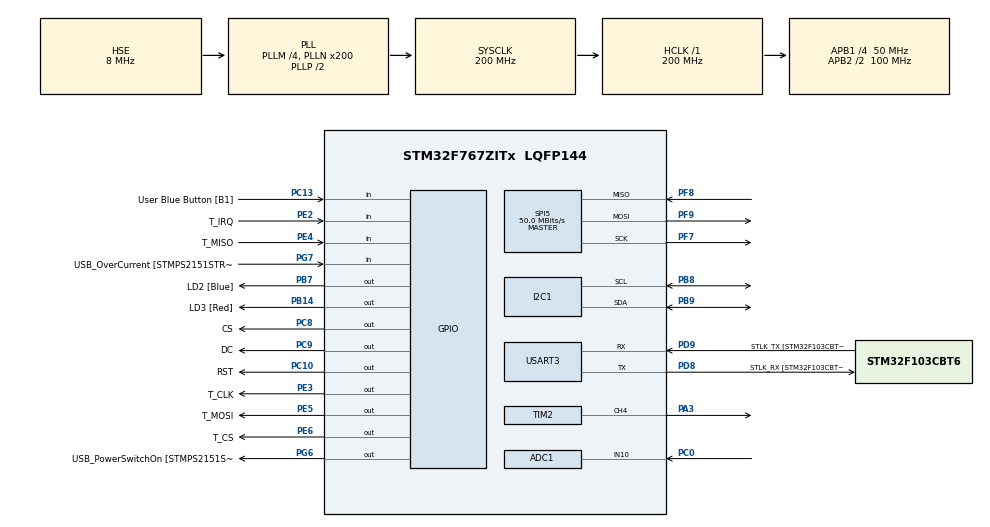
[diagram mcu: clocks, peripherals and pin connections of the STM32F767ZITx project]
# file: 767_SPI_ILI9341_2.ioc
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ADC1.Channel-0\#ChannelRegularConversion=ADC_CHANNEL_10
ADC1.ContinuousConvMode=ENABLE
ADC1.EOCSelection=ADC_EOC_SEQ_CONV
ADC1.NbrOfConversionFlag=1
ADC1.Rank-0\#ChannelRegularConversion=1
ADC1.SamplingTime-0\#ChannelRegularConversion=ADC_SAMPLETIME_3CYCLES
ADC1.master=1
CORTEX_M7.ART_ACCLERATOR_ENABLE=1
CORTEX_M7.CPU_DCache=Enabled
CORTEX_M7.CPU_ICache=Enabled
CORTEX_M7.PREFETCH_ENABLE=1
I2C1.Timing=0x00C0EAFF
Mcu.Family=STM32F7
Mcu.Name=STM32F767ZITx
Mcu.Package=LQFP144
NVIC.PriorityGroup=NVIC_PRIORITYGROUP_2
NVIC.TIM1_UP_TIM10_IRQn=true\:1\:0\:true\:false\:true\:true\:true\:true
PA1.GPIO_Label=RMII_REF_CLK [LAN8742A-CZ-TR_REFCLK0]
PA1.Signal=ETH_REF_CLK
PA13.GPIO_Label=TMS
PA13.Mode=Serial_Wire
PA13.Signal=SYS_JTMS-SWDIO
PA14.GPIO_Label=TCK
PA14.Mode=Serial_Wire
PA14.Signal=SYS_JTCK-SWCLK
PA2.Signal=S_TIM2_CH3
PA3.GPIO_Speed=GPIO_SPEED_FREQ_VERY_HIGH
PA3.Signal=S_TIM2_CH4
PA7.GPIO_Label=RMII_CRS_DV [LAN8742A-CZ-TR_CRS_DV]
PA7.Signal=ETH_CRS_DV
PB13.GPIO_Label=RMII_TXD1 [LAN8742A-CZ-TR_TXD1]
PB13.Signal=ETH_TXD1
PB14.GPIO_Label=LD3 [Red]
PB14.Signal=GPIO_Output
PB3.GPIO_Label=SWO
PB3.Signal=SYS_JTDO-SWO
PB7.GPIO_Label=LD2 [Blue]
PB7.Signal=GPIO_Output
PB8.Mode=I2C
PB8.Signal=I2C1_SCL
PB9.Mode=I2C
PB9.Signal=I2C1_SDA
PC0.Signal=ADCx_IN10
PC1.GPIO_Label=RMII_MDC [LAN8742A-CZ-TR_MDC]
PC1.Signal=ETH_MDC
PC10.GPIO_Label=RST
PC10.GPIO_Speed=GPIO_SPEED_FREQ_VERY_HIGH
PC10.Signal=GPIO_Output
PC13.GPIO_Label=User Blue Button [B1]
PC13.Signal=GPIO_Input
PC14/OSC32_IN.Mode=LSE-External-Oscillator
PC14/OSC32_IN.Signal=RCC_OSC32_IN
PC15/OSC32_OUT.Mode=LSE-External-Oscillator
PC15/OSC32_OUT.Signal=RCC_OSC32_OUT
PC4.GPIO_Label=RMII_RXD0 [LAN8742A-CZ-TR_RXD0]
PC4.Signal=ETH_RXD0
PC5.GPIO_Label=RMII_RXD1 [LAN8742A-CZ-TR_RXD1]
PC5.Signal=ETH_RXD1
PC8.GPIO_Label=CS
PC8.GPIO_Speed=GPIO_SPEED_FREQ_VERY_HIGH
PC8.Signal=GPIO_Output
PC9.GPIO_Label=DC
PC9.GPIO_Speed=GPIO_SPEED_FREQ_VERY_HIGH
PC9.Signal=GPIO_Output
PD8.GPIO_Label=STLK_RX [STM32F103CBT6_PA3]
PD8.Mode=Asynchronous
PD8.Signal=USART3_TX
PD9.GPIO_Label=STLK_TX [STM32F103CBT6_PA2]
PD9.Mode=Asynchronous
PD9.Signal=USART3_RX
PE2.GPIO_Label=T_IRQ
PE2.Signal=GPIO_Input
PE3.GPIO_Label=T_CLK
PE3.GPIO_Speed=GPIO_SPEED_FREQ_VERY_HIGH
PE3.Signal=GPIO_Output
PE4.GPIO_Label=T_MISO
PE4.Signal=GPIO_Input
PE5.GPIO_Label=T_MOSI
PE5.GPIO_Speed=GPIO_SPEED_FREQ_VERY_HIGH
PE5.Signal=GPIO_Output
PE6.GPIO_Label=T_CS
PE6.GPIO_Speed=GPIO_SPEED_FREQ_VERY_HIGH
PE6.Signal=GPIO_Output
PF7.Mode=Full_Duplex_Master
PF7.Signal=SPI5_SCK
PF8.Mode=Full_Duplex_Master
PF8.Signal=SPI5_MISO
PF9.Mode=Full_Duplex_Master
PF9.Signal=SPI5_MOSI
PG11.GPIO_Label=RMII_TX_EN [LAN8742A-CZ-TR_TXEN]
PG11.Signal=ETH_TX_EN
PG13.GPIO_Label=RMII_TXD0 [LAN8742A-CZ-TR_TXD0]
PG13.Signal=ETH_TXD0
PG6.GPIO_Label=USB_PowerSwitchOn [STMPS2151STR_EN]
PG6.Signal=GPIO_Output
PG7.GPIO_Label=USB_OverCurrent [STMPS2151STR_FAULT]
PG7.Signal=GPIO_Input
PH0/OSC_IN.GPIO_Label=MCO [STM32F103CBT6_PA8]
PH0/OSC_IN.Mode=HSE-External-Clock-Source
PH0/OSC_IN.Signal=RCC_OSC_IN
PH1/OSC_OUT.Mode=HSE-External-Clock-Source
PH1/OSC_OUT.Signal=RCC_OSC_OUT
ProjectManager.HeapSize=0x200
ProjectManager.StackSize=0x400
ProjectManager.TargetToolchain=STM32CubeIDE
RCC.48MHZClocksFreq_Value=24000000
RCC.AHBFreq_Value=200000000
RCC.APB1CLKDivider=RCC_HCLK_DIV4
RCC.APB1Freq_Value=50000000
RCC.APB1TimFreq_Value=100000000
RCC.APB2CLKDivider=RCC_HCLK_DIV2
RCC.APB2Freq_Value=100000000
RCC.APB2TimFreq_Value=200000000
RCC.CortexFreq_Value=200000000
RCC.HCLKFreq_Value=200000000
RCC.HSE_VALUE=8000000
RCC.HSI_VALUE=16000000
RCC.PLLM=4
RCC.PLLMUL=RCC_PLL_MUL9
RCC.PLLN=200
RCC.PLLQ=9
RCC.PLLSourceVirtual=RCC_PLLSOURCE_HSE
RCC.PRESCALERUSB=RCC_USBCLKSOURCE_PLL_DIV1_5
RCC.SYSCLKFreq_VALUE=200000000
RCC.SYSCLKSource=RCC_SYSCLKSOURCE_PLLCLK
RCC.SYSCLKSourceVirtual=RCC_SYSCLKSOURCE_PLLCLK
RCC.USBFreq_Value=44444444.44444445
RCC.VCOOutputFreq_Value=400000000
SH.ADCx_IN10.0=ADC1_IN10,IN10
SH.S_TIM2_CH3.0=TIM2_CH3
SH.S_TIM2_CH4.0=TIM2_CH4,PWM Generation4 CH4
SPI5.CalculateBaudRate=50.0 MBits/s
SPI5.DataSize=SPI_DATASIZE_8BIT
SPI5.Direction=SPI_DIRECTION_2LINES
SPI5.Mode=SPI_MODE_MASTER
SPI5.NSSPMode=SPI_NSS_PULSE_DISABLE
SPI5.VirtualType=VM_MASTER
TIM1.ClockDivision=TIM_CLOCKDIVISION_DIV1
TIM1.Period=10000-1
TIM1.Prescaler=21600-1
TIM2.Channel-PWM\ Generation4\ CH4=TIM_CHANNEL_4
TIM2.Period=10000-1
TIM2.Prescaler=108-1
TIM2.Pulse-PWM\ Generation4\ CH4=10000/4-1
USART3.VirtualMode-Asynchronous=VM_ASYNC
VP_RNG_VS_RNG.Mode=RNG_Activate
VP_TIM1_VS_ClockSourceINT.Mode=Internal
VP_TIM2_VS_ClockSourceINT.Mode=Internal
board=NUCLEO-F767ZI

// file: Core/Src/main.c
/* USER CODE BEGIN Header */
/**
  ******************************************************************************
  * @file           : main.c
  * @brief          : Main program body
  ******************************************************************************
  * @attention
  *
  * <h2><center>&copy; Copyright (c) 2021 STMicroelectronics.
  * All rights reserved.</center></h2>
  *
  * This software component is licensed by ST under BSD 3-Clause license,
  * the "License"; You may not use this file except in compliance with the
  * License. You may obtain a copy of the License at:
  *                        opensource.org/licenses/BSD-3-Clause
  *
  ******************************************************************************
  */
/* USER CODE END Header */
#include "main.h"
#include "adc.h"
#include "i2c.h"
#include "rng.h"
#include "spi.h"
#include "tim.h"
#include "usart.h"
#include "gpio.h"

/* USER CODE BEGIN Includes */
#include "stdio.h"
#include "ILI9341_Touchscreen.h"

#include "ILI9341_STM32_Driver.h"
#include "ILI9341_GFX.h"
#include "string.h"
/* USER CODE END Includes */

/* USER CODE BEGIN PTD */
typedef enum {
    MENU,
    PROFILE
} State;
/* USER CODE END PTD */

/* USER CODE BEGIN PV */
/* Private variables ---------------------------------------------------------*/
uint8_t red = 0;
uint8_t red_percent = 0;
uint8_t green = 0;
uint8_t green_percent = 0;
uint8_t blue = 0;
uint8_t blue_percent = 0;
float h=30.0,t=40.0;
uint8_t profile_counter = 0;
uint8_t profile_active = 0;
const uint16_t bill[] = {
		0xffff, 0xffff, 0xffff, 0xffff, 0xffff, 0xffff, 0xdf1c, 0xb5d7, 0xb596, 0xbe39, 0xefdf, 0xffff, 0xffff, 0xffff, 0xffff, 0xffff, 0xffff, 0xffff, 0xffff, 0xffff, 0xffff, 0xffff, 0xffff, 0xffff, 0xffff, 0xffff, 0xffff, 0xffff, 0xffff, 0xf7df, 0xf7be, 0xf7be, 0xf7be, 0xf7be, 0xf7be, 0xf7be, 0xf7be, 0xef9e, 0xdf3d, 0xb69c, 0x8e1c, 0x9ebf, 0xaf1f, 0x9e9e, 0xb6dd, 0xefbf, 0xffff, 0xf7df, 0xdf3c, 0xdf1c, 0xef7e, 0xef7e, 0xe77d, 0xef7e, 0xe75d, 0xe75d, 0xe75d, 0xe77d, 0xef7e, 0xef7e, 0xef7e, 0xe77d, 0xe75d, 0xe75d, 0xe73d, 0xe73d, 0xe73d, 0xe75d, 0xe73d, 0xe71c, 0xdefc, 0xe75d, 0xffff, 0xffff, 0xffff, 0xffff, 0xf7df, 0xf7be, 0xef7e, 0xe73c,
		0xffff, 0xffff, 0xffff, 0xffff, 0xffff, 0xffff, 0xef7e, 0xceba, 0xbe39, 0xc69a, 0xf7bf, 0xffff, 0xffff, 0xffff, 0xffff, 0xffff, 0xffff, 0xffff, 0xffff, 0xffff, 0xffff, 0xffff, 0xffff, 0xffff, 0xffff, 0xffff, 0xffff, 0xffff, 0xffff, 0xf7df, 0xf79e, 0xf7be, 0xf7be, 0xf7be, 0xf7be, 0xf7be, 0xf79e, 0xf7bf, 0xdf5e, 0xb69c, 0x95fa, 0x95fa, 0x9e1b, 0x9e7d, 0xa63b, 0x9514, 0x9d35, 0x9d35, 0x9d14, 0xa555, 0xadd7, 0xe75d, 0xef7e, 0xe75d, 0xe75d, 0xe75d, 0xe75d, 0xef7e, 0xef7e, 0xef7e, 0xef7e, 0xef7e, 0xe77d, 0xe75d, 0xe73d, 0xe73d, 0xe73d, 0xe73d, 0xe73d, 0xe73d, 0xe71c, 0xef5d, 0xffff, 0xffff, 0xffff, 0xffdf, 0xf7df, 0xf7be, 0xef7e, 0xef5c,
		0xffff, 0xffff, 0xffff, 0xffff, 0xffff, 0xffff, 0xffff, 0xf7df, 0xefbe, 0xef9e, 0xffdf, 0xffff, 0xffff, 0xffff, 0xffff, 0xffff, 0xffff, 0xffff, 0xffff, 0xffff, 0xffff, 0xffff, 0xffff, 0xffff, 0xffff, 0xffff, 0xffff, 0xffff, 0xffff, 0xf7bf, 0xef9e, 0xf79e, 0xf7be, 0xf7be, 0xf7be, 0xf7be, 0xffff, 0xdf1c, 0xadd8, 0x7c52, 0x52cc, 0x424a, 0x4249, 0x530d, 0x4a8b, 0x2966, 0x2145, 0x2966, 0x39e8, 0x73af, 0x636d, 0x94d3, 0xce7a, 0xceba, 0xef7e, 0xe75d, 0xe75d, 0xe77d, 0xef7e, 0xef7e, 0xef7e, 0xef7e, 0xef7d, 0xe75d, 0xe73d, 0xe73d, 0xe75d, 0xe75d, 0xe75d, 0xef5d, 0xef3d, 0xef7e, 0xffff, 0xffff, 0xffff, 0xffdf, 0xf7df, 0xf7be, 0xef9e, 0xe75d,
		0xffff, 0xffff, 0xffff, 0xffff, 0xffff, 0xffff, 0xffff, 0xffff, 0xffff, 0xffff, 0xffff, 0xffff, 0xffff, 0xffff, 0xffff, 0xffff, 0xffff, 0xffff, 0xffff, 0xffff, 0xffff, 0xffff, 0xffff, 0xffff, 0xffff, 0xffff, 0xffff, 0xffff, 0xffff, 0xf7bf, 0xef9e, 0xf7be, 0xf7be, 0xf7be, 0xf7df, 0xffdf, 0xbe38, 0x636e, 0x5b0c, 0x52ec, 0x39e8, 0x39e8, 0x31c7, 0x31a7, 0x31a6, 0x3186, 0x3186, 0x2966, 0x3186, 0x3186, 0x31a7, 0x4249, 0x8451, 0xad96, 0xef7e, 0xe75d, 0xe75d, 0xe75d, 0xef7e, 0xef7e, 0xef7e, 0xef7d, 0xef5d, 0xe75d, 0xe73d, 0xe73d, 0xef7e, 0xef7e, 0xef7e, 0xef7d, 0xef5d, 0xef7e, 0xffff, 0xffff, 0xffff, 0xffdf, 0xf7df, 0xf7bf, 0xef9e, 0xef5d,
		0xffff, 0xffff, 0xffff, 0xffff, 0xffff, 0xffff, 0xffff, 0xffff, 0xffff, 0xffff, 0xffff, 0xffff, 0xffff, 0xffff, 0xffff, 0xffff, 0xffff, 0xffff, 0xffff, 0xffff, 0xffff, 0xffff, 0xffff, 0xffff, 0xffff, 0xffff, 0xffff, 0xffff, 0xffff, 0xf7df, 0xef9e, 0xf7be, 0xf7de, 0xffff, 0xffff, 0xa535, 0x4a6a, 0x4a8a, 0x4a8a, 0x4249, 0x39e8, 0x31c7, 0x3186, 0x2986, 0x31c7, 0x3186, 0x2966, 0x2966, 0x2966, 0x3186, 0x3186, 0x3186, 0x3a08, 0x52cb, 0xa555, 0xe77e, 0xe77e, 0xe75d, 0xe77d, 0xef7e, 0xef7e, 0xef5d, 0xef5d, 0xe73d, 0xe73d, 0xe73d, 0xe75d, 0xe75d, 0xe75d, 0xe75d, 0xe75d, 0xef7e, 0xffdf, 0xffff, 0xffff, 0xffdf, 0xf7df, 0xf7be, 0xef7e, 0xef5d,
		0xffff, 0xffff, 0xffff, 0xffff, 0xffff, 0xffff, 0xffff, 0xffff, 0xffff, 0xffff, 0xffff, 0xffff, 0xffff, 0xffff, 0xffff, 0xffff, 0xffff, 0xffff, 0xffff, 0xffff, 0xffff, 0xffff, 0xffff, 0xffff, 0xffff, 0xffff, 0xffff, 0xffff, 0xffff, 0xf7df, 0xef9e, 0xf7be, 0xffff, 0xdf1c, 0x8c92, 0x4a6a, 0x4a8a, 0x4a6a, 0x39e8, 0x31c7, 0x31a7, 0x2986, 0x31a7, 0x2986, 0x2986, 0x2966, 0x2966, 0x2945, 0x2145, 0x2125, 0x2965, 0x2965, 0x2965, 0x2965, 0x3a08, 0x94f4, 0xe75d, 0xef7e, 0xe77d, 0xef7d, 0xef7e, 0xef7e, 0xef5d, 0xe75d, 0xe75d, 0xe75d, 0xe77e, 0xef7e, 0xef7e, 0xef9e, 0xef9e, 0xf7bf, 0xffff, 0xffff, 0xffff, 0xffdf, 0xf7df, 0xf7be, 0xef7d, 0xe73c,
		0xffff, 0xffff, 0xffff, 0xffff, 0xffff, 0xffff, 0xffff, 0xffff, 0xffff, 0xffff, 0xffff, 0xffff, 0xffff, 0xffff, 0xffff, 0xffff, 0xffff, 0xffff, 0xffff, 0xffff, 0xffff, 0xffff, 0xffff, 0xffff, 0xffff, 0xffff, 0xffff, 0xffff, 0xffff, 0xf7df, 0xef9e, 0xf7df, 0xef9e, 0x7c31, 0x424a, 0x4a6a, 0x4249, 0x31c7, 0x31a7, 0x2986, 0x2145, 0x2945, 0x31a7, 0x2946, 0x2966, 0x2946, 0x2125, 0x2145, 0x2945, 0x2145, 0x2145, 0x2945, 0x2945, 0x2966, 0x3165, 0x2965, 0xa575, 0xf7bf, 0xef7d, 0xef7d, 0xef7d, 0xef7d, 0xe75d, 0xe75d, 0xf7bf, 0xffff, 0xffff, 0xffff, 0xffff, 0xffff, 0xffff, 0xffff, 0xffff, 0xffff, 0xffff, 0xffdf, 0xf7df, 0xf7bf, 0xef7d, 0xe73c,
		0xffff, 0xffff, 0xffff, 0xffff, 0xffff, 0xffff, 0xffff, 0xffff, 0xffff, 0xffff, 0xffff, 0xffff, 0xffff, 0xffff, 0xffff, 0xffff, 0xffff, 0xffff, 0xffff, 0xffff, 0xffff, 0xffff, 0xffff, 0xffff, 0xffff, 0xffff, 0xffff, 0xffff, 0xffff, 0xf7df, 0xefbe, 0xffff, 0xc639, 0x4a6a, 0x4a6a, 0x4a8b, 0x3a08, 0x31a7, 0x2986, 0x2966, 0x2966, 0x3186, 0x3186, 0x2966, 0x2945, 0x2945, 0x3186, 0x3186, 0x3186, 0x2966, 0x2946, 0x2966, 0x2966, 0x2945, 0x3186, 0x2965, 0x4a49, 0xbe18, 0xef9e, 0xe75d, 0xe75d, 0xe73d, 0xdefc, 0xdf1c, 0xf7df, 0xffff, 0xffff, 0xffff, 0xffff, 0xffff, 0xffff, 0xffff, 0xffff, 0xffff, 0xffff, 0xf7df, 0xf7df, 0xf7bf, 0xef7e, 0xe73d,
		0xffff, 0xffff, 0xffff, 0xffff, 0xffff, 0xffff, 0xffff, 0xffff, 0xffff, 0xffff, 0xffff, 0xffff, 0xffff, 0xffff, 0xffff, 0xffff, 0xffff, 0xffff, 0xffff, 0xffff, 0xffff, 0xffff, 0xffff, 0xffff, 0xffff, 0xffff, 0xffff, 0xffff, 0xffff, 0xffff, 0xffff, 0xffff, 0x94d3, 0x4a6a, 0x4a8a, 0x4229, 0x39c8, 0x2966, 0x2966, 0x3986, 0x41a6, 0x41a6, 0x3186, 0x2966, 0x2966, 0x31a7, 0x3186, 0x2966, 0x2945, 0x2945, 0x2965, 0x2945, 0x2966, 0x2966, 0x2945, 0x3186, 0x2945, 0x4a6a, 0xcefd, 0xe79f, 0xdf5e, 0xd71d, 0xbe9b, 0xbe9b, 0xf7df, 0xffff, 0xffff, 0xffff, 0xffff, 0xffff, 0xffff, 0xffff, 0xffff, 0xffff, 0xffff, 0xf7df, 0xf7df, 0xf7bf, 0xef9e, 0xef5d,
		0xffff, 0xffff, 0xffff, 0xffff, 0xffff, 0xffff, 0xffff, 0xffff, 0xffff, 0xf7df, 0xe79e, 0xffff, 0xffff, 0xffff, 0xffff, 0xffff, 0xffff, 0xffff, 0xffff, 0xffff, 0xffff, 0xffff, 0xffff, 0xffff, 0xffff, 0xffff, 0xffff, 0xffff, 0xffff, 0xffff, 0xffff, 0xffff, 0x6bcf, 0x4a8a, 0x4a6a, 0x31c7, 0x3186, 0x2966, 0x3166, 0x5a07, 0x7268, 0x5207, 0x39a7, 0x2966, 0x31a7, 0x3186, 0x2965, 0x2945, 0x2125, 0x2125, 0x2945, 0x2945, 0x2945, 0x2946, 0x2966, 0x3186, 0x3186, 0x2945, 0x9536, 0xdfbf, 0xdf5e, 0xcf1d, 0xae7c, 0x9e5b, 0xf7df, 0xffff, 0xffff, 0xffff, 0xffff, 0xffff, 0xffff, 0xffff, 0xffff, 0xffff, 0xffff, 0xffdf, 0xf7df, 0xf7bf, 0xef9e, 0xef5d,
		0xffff, 0xffff, 0xffff, 0xffff, 0xffff, 0xffff, 0xffff, 0xffff, 0xffff, 0xffff, 0xf7df, 0xffff, 0xffff, 0xffff, 0xffff, 0xffff, 0xffff, 0xffff, 0xffff, 0xffff, 0xffff, 0xffff, 0xffff, 0xffff, 0xffff, 0xffff, 0xffff, 0xffff, 0xffff, 0xffff, 0xffff, 0xc67a, 0x52cc, 0x52ab, 0x4229, 0x2966, 0x2966, 0x49e7, 0x41a6, 0x6247, 0xa36a, 0x7a88, 0x5207, 0x3186, 0x2966, 0x2945, 0x3165, 0x2965, 0x2966, 0x2945, 0x2125, 0x2945, 0x2945, 0x2145, 0x2966, 0x3186, 0x3186, 0x3986, 0x634e, 0xd75e, 0xe79f, 0xdf7e, 0xcf1e, 0xc71e, 0xf7df, 0xffff, 0xffff, 0xffff, 0xffff, 0xffff, 0xffff, 0xffff, 0xffff, 0xffff, 0xffff, 0xf7df, 0xf7df, 0xf7bf, 0xef9e, 0xef5d,
		0xffff, 0xffff, 0xffff, 0xffff, 0xffff, 0xffff, 0xffff, 0xffff, 0xffff, 0xffff, 0xffff, 0xffff, 0xffff, 0xffff, 0xffff, 0xffff, 0xffff, 0xffff, 0xffff, 0xffff, 0xffff, 0xffff, 0xffff, 0xffff, 0xffff, 0xffff, 0xffff, 0xffff, 0xffff, 0xffff, 0xffff, 0x6baf, 0x4a6a, 0x52ab, 0x41e8, 0x2966, 0x6227, 0x9329, 0x9b6b, 0x8b09, 0xab8a, 0xab6a, 0x82a8, 0x6a27, 0x59e6, 0x4185, 0x3965, 0x3965, 0x3165, 0x2966, 0x2945, 0x2945, 0x2946, 0x2125, 0x2986, 0x2986, 0x3186, 0x39a6, 0x39e7, 0xadf8, 0xf7df, 0xef9e, 0xe77e, 0xdf7e, 0xf7df, 0xffff, 0xffff, 0xffff, 0xffff, 0xffff, 0xffff, 0xffff, 0xffff, 0xffff, 0xffff, 0xf7df, 0xf7df, 0xf7bf, 0xef9e, 0xef5d,
		0xffff, 0xffff, 0xffff, 0xffff, 0xffff, 0xffff, 0xffff, 0xffff, 0xffff, 0xffff, 0xffff, 0xffff, 0xffff, 0xffff, 0xffff, 0xffff, 0xffff, 0xffff, 0xffff, 0xffff, 0xffff, 0xffff, 0xffff, 0xffff, 0xffff, 0xffff, 0xffff, 0xffff, 0xffff, 0xffff, 0xf7df, 0x73f0, 0x4a6a, 0x4a6a, 0x39a7, 0x6227, 0xabab, 0xabec, 0xabcc, 0x934a, 0x9b4a, 0xabab, 0xab8a, 0xa308, 0x92c7, 0x8aa7, 0x7a67, 0x6a26, 0x59c6, 0x3986, 0x3165, 0x2965, 0x2945, 0x2945, 0x31a6, 0x2966, 0x31a6, 0x39c7, 0x2945, 0x5b2d, 0xefbf, 0xefbf, 0xe79e, 0xe79e, 0xf7ff, 0xffff, 0xffff, 0xffff, 0xffff, 0xffff, 0xffff, 0xffff, 0xffff, 0xffff, 0xffff, 0xffdf, 0xf7df, 0xf7bf, 0xf79e, 0xef5d,
		0xffff, 0xffff, 0xffff, 0xffff, 0xffff, 0xffff, 0xffff, 0xffff, 0xffff, 0xffff, 0xffff, 0xffff, 0xffff, 0xffff, 0xffff, 0xffff, 0xffff, 0xffff, 0xffff, 0xffff, 0xffff, 0xffff, 0xffff, 0xffff, 0xffff, 0xffff, 0xffff, 0xffff, 0xffff, 0xffff, 0xd71c, 0x632d, 0x4a69, 0x41e7, 0x72ca, 0xb46f, 0xbcb1, 0xa3ed, 0x830a, 0x6a68, 0x5a48, 0x7289, 0x9b4a, 0xab8a, 0xa329, 0x92e8, 0x92c8, 0x8287, 0x6226, 0x49a6, 0x3165, 0x2965, 0x2945, 0x3186, 0x3186, 0x3186, 0x39c7, 0x39c7, 0x3166, 0x3a28, 0xcf1d, 0xe7bf, 0xd75f, 0xcf5f, 0xf7df, 0xffff, 0xffff, 0xffff, 0xffff, 0xffff, 0xffff, 0xffff, 0xffff, 0xffff, 0xffff, 0xf7df, 0xf7df, 0xf7bf, 0xf79e, 0xef7d,
		0xffff, 0xffff, 0xffff, 0xffff, 0xffff, 0xffff, 0xffff, 0xffff, 0xffff, 0xffff, 0xffff, 0xffff, 0xffff, 0xffff, 0xffff, 0xffff, 0xffff, 0xffff, 0xffff, 0xffff, 0xffff, 0xffff, 0xffff, 0xffff, 0xffff, 0xffff, 0xffff, 0xffff, 0xffff, 0xffde, 0xce58, 0x6b6e, 0x41e8, 0x836d, 0xddd5, 0xd5f6, 0xc554, 0xb490, 0xb42e, 0x9b6b, 0x7ac9, 0x5207, 0x5207, 0x82e9, 0xa36a, 0xa36a, 0x9b29, 0x92e8, 0x7a67, 0x51c5, 0x2945, 0x2945, 0x2965, 0x3186, 0x2966, 0x31a6, 0x31a6, 0x3186, 0x31a6, 0x4228, 0xcedc, 0xe7bf, 0xd75e, 0xcf5e, 0xf7df, 0xffff, 0xffff, 0xffff, 0xffff, 0xffff, 0xffff, 0xffff, 0xffff, 0xffff, 0xffff, 0xffdf, 0xf7df, 0xf7bf, 0xf79e, 0xef7d,
		0xffff, 0xffff, 0xffff, 0xffff, 0xffff, 0xffff, 0xffff, 0xffff, 0xffff, 0xffff, 0xffff, 0xffff, 0xffff, 0xffff, 0xffff, 0xffff, 0xffff, 0xffff, 0xffff, 0xffff, 0xffff, 0xffff, 0xffff, 0xffff, 0xffff, 0xffff, 0xffff, 0xffff, 0xffbe, 0xd3ee, 0xbbed, 0x62eb, 0x5269, 0xd5d6, 0xddf6, 0xcd32, 0xbc6e, 0xabcc, 0xa38b, 0xa36a, 0xab6a, 0x8ae9, 0x6a88, 0x6248, 0x82e9, 0xab8a, 0xab8a, 0xa36a, 0x9b29, 0x7a67, 0x4985, 0x3145, 0x2125, 0x2945, 0x2965, 0x3186, 0x3166, 0x3186, 0x3186, 0x52aa, 0xdf5d, 0xf7bf, 0xef9e, 0xe79e, 0xf7df, 0xffff, 0xffff, 0xffff, 0xffff, 0xffff, 0xffff, 0xffff, 0xffff, 0xffff, 0xffff, 0xffdf, 0xf7df, 0xf7bf, 0xf79e, 0xef7d,
		0xffff, 0xffff, 0xffff, 0xffff, 0xffff, 0xffff, 0xffff, 0xffff, 0xffff, 0xffff, 0xffff, 0xffff, 0xffff, 0xffff, 0xffff, 0xffff, 0xffff, 0xffff, 0xffff, 0xffff, 0xffff, 0xffff, 0xffff, 0xffff, 0xffff, 0xffff, 0xffff, 0xffff, 0xe595, 0xcaa8, 0xcc90, 0x6b2c, 0x9c50, 0xe678, 0xcd53, 0xbc6e, 0xb3cb, 0x92e8, 0x6a68, 0x4208, 0x51e6, 0x92c8, 0x9ae8, 0x8b09, 0x82c8, 0x9b29, 0xab8a, 0xab8b, 0xa38b, 0xab8b, 0xa36a, 0x8ae9, 0x59e6, 0x2125, 0x2945, 0x3186, 0x3186, 0x3186, 0x3186, 0x6b8e, 0xf7bf, 0xf7bf, 0xf7be, 0xf7be, 0xf7be, 0xffdf, 0xffff, 0xffff, 0xffff, 0xffff, 0xf7df, 0xf7df, 0xffff, 0xffff, 0xffff, 0xffdf, 0xf7df, 0xf7bf, 0xf79e, 0xef7d,
		0xffff, 0xffff, 0xffff, 0xffff, 0xffff, 0xffff, 0xffff, 0xffff, 0xffff, 0xffff, 0xffff, 0xffff, 0xffff, 0xffff, 0xffff, 0xffff, 0xffff, 0xffff, 0xffff, 0xffff, 0xffff, 0xffff, 0xffff, 0xffff, 0xffff, 0xffff, 0xffff, 0xffff, 0xd470, 0xcb8b, 0xbbcc, 0xa450, 0xde99, 0xde58, 0xccf0, 0xbc4e, 0xb40c, 0xb3cb, 0xab6a, 0x7268, 0x6268, 0x6a47, 0x92a7, 0xab6a, 0xab8a, 0xa34a, 0xa36a, 0x9329, 0x6a88, 0x6248, 0x7ae9, 0x8b2a, 0x9329, 0x6207, 0x3165, 0x3186, 0x2965, 0x3166, 0x39c6, 0xad55, 0xffff, 0xf79e, 0xf7be, 0xf7be, 0xf79e, 0xf79e, 0xef9e, 0xef7e, 0xef7d, 0xe75d, 0xe73d, 0xe73d, 0xf7df, 0xffff, 0xffff, 0xffdf, 0xf7df, 0xf7bf, 0xf79e, 0xef7d,
		0xffff, 0xffff, 0xffff, 0xffff, 0xffff, 0xffff, 0xffff, 0xffff, 0xffff, 0xffff, 0xffff, 0xffff, 0xffff, 0xffff, 0xffff, 0xffff, 0xffff, 0xffff, 0xffff, 0xffff, 0xffff, 0xffff, 0xffff, 0xffff, 0xffff, 0xffff, 0xffff, 0xffff, 0xd4d2, 0xb287, 0xb30a, 0xd637, 0xef1b, 0xddf6, 0xccd0, 0xc44e, 0xbbec, 0xb3ab, 0xab8a, 0xab29, 0x9ae8, 0x82a7, 0x92e8, 0xab8a, 0xb3cb, 0xabaa, 0xa36a, 0x9b09, 0x82a8, 0x5a27, 0x49e6, 0x5207, 0x6288, 0x9b29, 0x51c6, 0x2945, 0x3186, 0x3186, 0x528a, 0xe75c, 0xf7be, 0xef7d, 0xef7d, 0xf77d, 0xef7d, 0xef7d, 0xef5d, 0xef5d, 0xe73c, 0xe71c, 0xdf1c, 0xdf1c, 0xf7bf, 0xffff, 0xffff, 0xffdf, 0xf7df, 0xf7bf, 0xf79e, 0xef7d,
		0xe75d, 0xffdf, 0xffff, 0xffff, 0xffff, 0xffff, 0xffff, 0xf7df, 0xf7df, 0xf7ff, 0xffff, 0xffff, 0xffff, 0xffff, 0xffff, 0xffff, 0xffff, 0xffff, 0xffff, 0xffff, 0xffff, 0xffff, 0xffff, 0xffff, 0xffff, 0xffff, 0xffff, 0xffdf, 0xc46f, 0xaa47, 0xc470, 0xe71b, 0xe699, 0xd594, 0xccd0, 0xc48f, 0xc42d, 0xb3cb, 0xab8a, 0xa349, 0xa329, 0xab49, 0xab69, 0xb3aa, 0xb3aa, 0xb3ca, 0xab49, 0x92a7, 0x8287, 0x92e8, 0xa36a, 0x934a, 0x72c9, 0x8b09, 0x5a07, 0x2125, 0x3186, 0x2965, 0x9492, 0xf7df, 0xef7d, 0xef7d, 0xef5d, 0xef5d, 0xef5c, 0xef5c, 0xe73d, 0xef5d, 0xe73c, 0xdf1c, 0xdf1c, 0xdf1c, 0xf7bf, 0xffff, 0xffff, 0xffdf, 0xf7df, 0xf7bf, 0xf79e, 0xef7d,
		0xd6ba, 0xf7df, 0xffff, 0xffff, 0xffff, 0xffff, 0xef9e, 0xbe38, 0xbe17, 0xbe38, 0xd71c, 0xf7df, 0xffff, 0xffff, 0xffff, 0xffff, 0xffff, 0xefbf, 0xe79e, 0xf7df, 0xf7df, 0xf7ff, 0xf7ff, 0xffff, 0xffff, 0xf7ff, 0xffff, 0xffdf, 0xccd1, 0xbbcc, 0xbc90, 0xe6fb, 0xde58, 0xd594, 0xccf1, 0xccb0, 0xc46e, 0xc42d, 0xbc0c, 0xbbcb, 0xbbeb, 0xbbec, 0xbc0c, 0xbc0c, 0xbc0c, 0xbbcb, 0xa308, 0x7247, 0x4186, 0x3986, 0x7287, 0xabab, 0xabed, 0xa38b, 0x5a07, 0x2945, 0x2945, 0x52aa, 0xe73c, 0xf79e, 0xef7d, 0xef7d, 0xef7d, 0xef7d, 0xef5d, 0xe75d, 0xe73d, 0xe75d, 0xe73d, 0xdf1c, 0xdf1c, 0xdf1c, 0xf7bf, 0xffff, 0xffff, 0xffdf, 0xf7df, 0xf7bf, 0xf7be, 0xef7e,
		0xdeda, 0xf7df, 0xffff, 0xffff, 0xffff, 0xffff, 0xe77e, 0xb5b5, 0xad32, 0x9d12, 0xc67a, 0xf7bf, 0xffff, 0xffff, 0xffff, 0xffff, 0xffff, 0xe79e, 0xdf7e, 0xefbf, 0xf7df, 0xf7ff, 0xf7ff, 0xffff, 0xffff, 0xf7ff, 0xffff, 0xffff, 0xe658, 0xb34a, 0xbc2e, 0xe6da, 0xde37, 0xd594, 0xcd11, 0xccb0, 0xc46e, 0xc46e, 0xbc2d, 0xbbec, 0xbc0c, 0xc42d, 0xc44d, 0xc42d, 0xc42d, 0xbc0c, 0xab69, 0x92c8, 0x8a87, 0x82c9, 0x6227, 0x7a46, 0xbc4d, 0xbc6e, 0x51e6, 0x2925, 0x41c7, 0xc659, 0xef9e, 0xef7d, 0xef7d, 0xef7d, 0xef7d, 0xef7d, 0xef7d, 0xef5d, 0xe75d, 0xe73d, 0xe73c, 0xdf1c, 0xdf1c, 0xdf1c, 0xf7be, 0xffff, 0xffff, 0xffdf, 0xf7df, 0xf7bf, 0xf79e, 0xef7e,
		0xdefb, 0xf7df, 0xffff, 0xffff, 0xffff, 0xffff, 0xef9e, 0xc637, 0xbdb4, 0xad74, 0xc6bb, 0xefbf, 0xf7df, 0xf7df, 0xffff, 0xffff, 0xffff, 0xe7bf, 0xe79f, 0xefbf, 0xf7df, 0xf7ff, 0xf7ff, 0xffff, 0xffff, 0xefbf, 0xf7df, 0xffff, 0xffdf, 0xe699, 0xd5d6, 0xe699, 0xde16, 0xd553, 0xccd1, 0xc48f, 0xc46e, 0xc44d, 0xb3cb, 0xb3ab, 0xc46e, 0xc48f, 0xc46f, 0xbc2d, 0xc44d, 0xc44d, 0xbbeb, 0xab69, 0xa329, 0xb36a, 0xb3eb, 0xabab, 0xbc4d, 0xbc8f, 0x4185, 0x31a6, 0xad75, 0xffdf, 0xef7d, 0xef7d, 0xef7d, 0xe75d, 0xef5d, 0xef7d, 0xf79d, 0xf79d, 0xef7d, 0xe75d, 0xe73c, 0xe73c, 0xdf1c, 0xdf1c, 0xefbe, 0xffff, 0xffff, 0xffdf, 0xf7df, 0xf7bf, 0xf7be, 0xef9e,
		0xdefb, 0xf7df, 0xffff, 0xffff, 0xffff, 0xffff, 0xef9e, 0xc657, 0xb5d5, 0xa574, 0xbe9a, 0xef9e, 0xef9f, 0xef9e, 0xf7df, 0xffff, 0xffff, 0xf7df, 0xefdf, 0xf7df, 0xf7df, 0xf7df, 0xf7df, 0xf7df, 0xf7df, 0xefbf, 0xf7df, 0xffff, 0xffff, 0xffff, 0xef5d, 0xde58, 0xddd5, 0xd532, 0xccb0, 0xc48f, 0xc44d, 0xbc0c, 0xb38a, 0xb3ab, 0xabac, 0xa3ac, 0xcc8f, 0xc48e, 0xccaf, 0xc44e, 0xbc2c, 0xbbcb, 0xb3aa, 0xb3aa, 0xbbec, 0xbc4d, 0xc4d0, 0xac90, 0x39a6, 0xad34, 0xffdf, 0xf77d, 0xef7d, 0xef7d, 0xef5d, 0xe73d, 0xe73d, 0xef5d, 0xf79d, 0xf79e, 0xf79d, 0xef5d, 0xe73c, 0xdf1c, 0xdf1c, 0xdf1c, 0xefbe, 0xffff, 0xffff, 0xffdf, 0xf7df, 0xf7bf, 0xf7be, 0xef9e,
		0xdf1b, 0xf7df, 0xffff, 0xffff, 0xffff, 0xffff, 0xef9e, 0xc658, 0xb5b5, 0x9d54, 0xbe7a, 0xef9e, 0xefbe, 0xef9e, 0xf7bf, 0xffff, 0xffff, 0xffff, 0xffff, 0xffff, 0xffff, 0xf7df, 0xf7ff, 0xf7ff, 0xffff, 0xffff, 0xffff, 0xffff, 0xffff, 0xf7df, 0xe71c, 0xde57, 0xddb4, 0xcd11, 0xccaf, 0xc46e, 0xbc2d, 0xbc2d, 0xbc2d, 0xab8b, 0x8a88, 0x92c9, 0xbbec, 0xabab, 0xb3cc, 0xc46f, 0xbbec, 0xbbec, 0xbc0c, 0xc40c, 0xc44d, 0xc44e, 0xd552, 0x942f, 0x8226, 0xdd94, 0xf7bf, 0xef7d, 0xef7d, 0xef7d, 0xe75d, 0xe71c, 0xdf1c, 0xe73d, 0xef7d, 0xf79d, 0xf79d, 0xef5d, 0xe73c, 0xdf1c, 0xdf1c, 0xdefc, 0xef9e, 0xffff, 0xffff, 0xffdf, 0xf7df, 0xf7bf, 0xf7be, 0xef9e,
		0xdf1b, 0xf7df, 0xffff, 0xffff, 0xffff, 0xffff, 0xef9e, 0xb5f6, 0xa533, 0x8cf2, 0xb639, 0xef9f, 0xf7df, 0xf7bf, 0xf7df, 0xffff, 0xffff, 0xffff, 0xffff, 0xffff, 0xffff, 0xffff, 0xffff, 0xffff, 0xffff, 0xffff, 0xffff, 0xffff, 0xffff, 0xf7df, 0xe6fb, 0xde37, 0xdd94, 0xcd11, 0xc48e, 0xbc0c, 0xbc0c, 0xbc8f, 0xc48f, 0xbc4e, 0xbc2d, 0xb3cc, 0xb3ab, 0x9b09, 0x8a87, 0xbbec, 0xb3cb, 0xbbec, 0xc42d, 0xc46e, 0xcc8f, 0xccaf, 0xd573, 0x8b8d, 0xba45, 0xde17, 0xef9e, 0xef5d, 0xef7e, 0xef7e, 0xef5d, 0xdf3c, 0xdefc, 0xdf1c, 0xe75d, 0xef7d, 0xef7d, 0xef7d, 0xe73c, 0xdf1c, 0xdf1c, 0xdf1c, 0xef9e, 0xffff, 0xffff, 0xffff, 0xf7df, 0xf7bf, 0xf7be, 0xef7e,
		0xdefb, 0xf7df, 0xffff, 0xffff, 0xffff, 0xffff, 0xe79e, 0x9534, 0x73ef, 0x6bce, 0xa5f8, 0xefbf, 0xffdf, 0xffff, 0xffff, 0xffff, 0xffff, 0xffff, 0xffff, 0xffff, 0xffff, 0xffff, 0xffff, 0xffff, 0xffff, 0xffff, 0xffff, 0xffff, 0xffff, 0xf7ff, 0xe71c, 0xde57, 0xd594, 0xccf0, 0xc44d, 0xab8a, 0xa34a, 0xb40d, 0xbc2e, 0xbc0d, 0xbbcc, 0xbbec, 0xb40c, 0xbc2d, 0xb3cc, 0xb3cc, 0xbbec, 0xbc0c, 0xc44e, 0xcc8f, 0xccd0, 0xccf0, 0xc4d1, 0xaae8, 0xcc2e, 0xe77e, 0xef5d, 0xef7d, 0xf79e, 0xf79e, 0xef7d, 0xe73d, 0xdefc, 0xdf1c, 0xe75d, 0xef7d, 0xf79d, 0xef7d, 0xe75d, 0xe73c, 0xe73c, 0xe73c, 0xf7be, 0xffff, 0xffff, 0xffff, 0xf7df, 0xf7bf, 0xf7be, 0xef7e,
		0xdefc, 0xffdf, 0xffff, 0xffff, 0xffff, 0xffff, 0xe79f, 0x6c31, 0x3a49, 0x428a, 0x9d97, 0xefbf, 0xffff, 0xffff, 0xffff, 0xffff, 0xffff, 0xffff, 0xffff, 0xffff, 0xffff, 0xffff, 0xffff, 0xffff, 0xffff, 0xffff, 0xffff, 0xffff, 0xffff, 0xffff, 0xef3c, 0xde57, 0xd594, 0xc4af, 0xbc4d, 0xab8a, 0x9b2a, 0x9aea, 0xa2a9, 0xa2c9, 0xaae9, 0xb34a, 0xb3ab, 0xbc2d, 0xbc6e, 0xbc2d, 0xbc0c, 0xc42d, 0xc44d, 0xc48e, 0xccd0, 0xcd31, 0xb38b, 0xbb8a, 0xe73c, 0xef9e, 0xef7d, 0xf79e, 0xf79e, 0xf79e, 0xf79e, 0xef5d, 0xe73c, 0xe73c, 0xef7d, 0xf79d, 0xf79e, 0xf79d, 0xef7d, 0xef5d, 0xe75d, 0xe75d, 0xf7be, 0xffff, 0xffff, 0xffff, 0xf7df, 0xf7bf, 0xf7be, 0xef9e,
		0xdefc, 0xf7df, 0xffff, 0xffff, 0xffff, 0xffff, 0xefbf, 0x6c31, 0x39e8, 0x426a, 0x9db8, 0xefbf, 0xffff, 0xffff, 0xffff, 0xffff, 0xffff, 0xffff, 0xffff, 0xffff, 0xffff, 0xffff, 0xffff, 0xffff, 0xffff, 0xffff, 0xffff, 0xffff, 0xffff, 0xffff, 0xe71c, 0xde37, 0xd594, 0xc4b0, 0xc46e, 0xc44d, 0xc44e, 0xc44e, 0xbb8c, 0xb2ca, 0xa288, 0xa268, 0xa2a8, 0xab4a, 0xb40d, 0xabab, 0xb3cb, 0xc42d, 0xc44d, 0xc46e, 0xc4af, 0xccd0, 0xab29, 0xd617, 0xefbf, 0xef7d, 0xef9e, 0xf79e, 0xf79e, 0xf79e, 0xf79e, 0xf79d, 0xef7d, 0xef7d, 0xf79d, 0xf79d, 0xf79d, 0xf79d, 0xef7d, 0xef7d, 0xef5d, 0xef5d, 0xf7be, 0xffff, 0xffff, 0xffff, 0xf7df, 0xf7bf, 0xf7be, 0xef9e,
		0xdf1c, 0xffdf, 0xffff, 0xffff, 0xffff, 0xffff, 0xefbf, 0x8492, 0x4228, 0x4aaa, 0xa5f8, 0xefbf, 0xffff, 0xffff, 0xffff, 0xffff, 0xffff, 0xffff, 0xffff, 0xffff, 0xffff, 0xffff, 0xffff, 0xffff, 0xffff, 0xffff, 0xffff, 0xffff, 0xffff, 0xffff, 0xe6ba, 0xd5b5, 0xd5b5, 0xcd52, 0xc4af, 0xc46e, 0xc42d, 0xbc2d, 0xbbec, 0xbb6b, 0xbb4b, 0xbb0a, 0xb30a, 0xab2a, 0x8a88, 0x8266, 0xb3aa, 0xc44d, 0xc46e, 0xbc4e, 0xc48f, 0xbc2d, 0xcd53, 0xef7e, 0xef7e, 0xef7d, 0xf79e, 0xf79e, 0xf79e, 0xf79e, 0xf79e, 0xf79d, 0xf79d, 0xf79d, 0xf79d, 0xf79d, 0xef7d, 0xef7d, 0xef7d, 0xef5d, 0xe75d, 0xe75c, 0xf7be, 0xffff, 0xffff, 0xffff, 0xf7df, 0xf7bf, 0xf7be, 0xef9e,
		0xdf1c, 0xffdf, 0xffff, 0xffff, 0xffff, 0xffff, 0xefbf, 0x94f3, 0x5a89, 0x630c, 0xadf9, 0xefbf, 0xffff, 0xffff, 0xffff, 0xffff, 0xffff, 0xffff, 0xffff, 0xffff, 0xffff, 0xffff, 0xffff, 0xffff, 0xffff, 0xffff, 0xffff, 0xffff, 0xf7ff, 0x9555, 0xd5f6, 0xcd32, 0xc4f1, 0xcd73, 0xc4d0, 0xc46e, 0xbc2d, 0xbbec, 0xbbcc, 0xb36a, 0xb36a, 0xb38b, 0xbbec, 0xc44d, 0xb3cb, 0xa349, 0xbc0c, 0xc46e, 0xc46e, 0xbc2d, 0xd5d6, 0xde79, 0xe75d, 0xe77e, 0xef5d, 0xef7d, 0xf79d, 0xf79d, 0xf79e, 0xf79e, 0xf79d, 0xf79d, 0xf79d, 0xf79d, 0xf79d, 0xef9d, 0xef7d, 0xef7d, 0xef5d, 0xe75c, 0xe73c, 0xe73c, 0xef9e, 0xffff, 0xffff, 0xffff, 0xf7df, 0xf7bf, 0xf7be, 0xef9e,
		0xdf1c, 0xffdf, 0xffff, 0xffff, 0xffff, 0xffff, 0xefbf, 0xa596, 0x7bef, 0x8431, 0xb639, 0xefbf, 0xffff, 0xffff, 0xffff, 0xffff, 0xffff, 0xffff, 0xffff, 0xffff, 0xffff, 0xffff, 0xffff, 0xffff, 0xffff, 0xffff, 0xffff, 0xefdf, 0x538f, 0x3a29, 0xe616, 0xc4b0, 0xb40d, 0xb46f, 0xc4f1, 0xc4af, 0xc48f, 0xc44d, 0xbbec, 0xb3ab, 0xb3ab, 0xbbec, 0xc42d, 0xc44d, 0xbc2c, 0xbbeb, 0xbc2c, 0xbc2c, 0xb3ec, 0xcdb5, 0xef9e, 0xef9e, 0xe75d, 0xe73d, 0xe75d, 0xef7d, 0xf79d, 0xf79d, 0xef9d, 0xf79d, 0xf79d, 0xf79d, 0xf79d, 0xf79d, 0xf79d, 0xef7d, 0xef7d, 0xef7d, 0xef5d, 0xe73c, 0xe71c, 0xdf1c, 0xef9e, 0xffff, 0xffff, 0xffff, 0xf7df, 0xf7bf, 0xf7be, 0xef9e,
		0xdf3d, 0xffdf, 0xffff, 0xffff, 0xffff, 0xffff, 0xefbf, 0xb618, 0x9cf4, 0x9cf4, 0xb63a, 0xefbf, 0xffff, 0xffff, 0xffff, 0xffff, 0xffff, 0xffff, 0xffff, 0xffff, 0xffff, 0xffff, 0xffff, 0xffff, 0xffff, 0xffff, 0xd73d, 0x5bd2, 0x08a4, 0x6b2c, 0xddb4, 0xbc6e, 0xb3cb, 0xab8a, 0xabec, 0xc48f, 0xc48f, 0xc44e, 0xbc2d, 0xbc0d, 0xbc2d, 0xc42d, 0xc42d, 0xbc0c, 0xbbeb, 0xb3ca, 0xab69, 0xb40c, 0xd637, 0xef9e, 0xef5d, 0xe73d, 0xe73d, 0xe73d, 0xe75d, 0xef7d, 0xef7d, 0xef7d, 0xef7d, 0xef9d, 0xf79d, 0xf79d, 0xef9d, 0xf79d, 0xef7d, 0xef7d, 0xef7d, 0xef5d, 0xe73c, 0xe73c, 0xdf1c, 0xdf1c, 0xef9e, 0xffff, 0xffff, 0xffff, 0xffdf, 0xf7bf, 0xf7be, 0xef7e,
		0xdf1c, 0xffdf, 0xffff, 0xffff, 0xffff, 0xffff, 0xefbf, 0xbe59, 0xa576, 0xa597, 0xc6bb, 0xefbf, 0xffff, 0xffff, 0xffff, 0xffff, 0xffff, 0xffff, 0xffff, 0xffff, 0xffff, 0xffff, 0xffff, 0xffff, 0xffff, 0xae19, 0x4b30, 0x31ca, 0x10e5, 0x7b2b, 0xd511, 0xbc2d, 0xb3ab, 0xab6a, 0xa349, 0xa36a, 0xb3cc, 0xbc0c, 0xbc2d, 0xc42d, 0xc44d, 0xc46e, 0xc44d, 0xbc0b, 0xab8a, 0xa38a, 0xbd12, 0xdf1c, 0xefbf, 0xe75d, 0xe75d, 0xe73d, 0xe73d, 0xe73c, 0xe73d, 0xef5d, 0xef7d, 0xef7d, 0xef7d, 0xf79e, 0xf79d, 0xef7d, 0xef7d, 0xef7d, 0xef7d, 0xef7d, 0xef5d, 0xe75c, 0xe73c, 0xdf1c, 0xdf1c, 0xdefc, 0xef9e, 0xffff, 0xffff, 0xffff, 0xf7df, 0xf7bf, 0xf7be, 0xef9e,
		0xe75d, 0xffff, 0xffff, 0xffff, 0xffff, 0xffff, 0xf7df, 0xe77e, 0xdf5d, 0xe77e, 0xef9e, 0xf7df, 0xffff, 0xffff, 0xffff, 0xffff, 0xffff, 0xffff, 0xffff, 0xffff, 0xffff, 0xffff, 0xdf3d, 0xae3a, 0x7474, 0x3aaf, 0x428e, 0x31a8, 0x1905, 0x7ac9, 0xc48e, 0xbc0c, 0xb3ab, 0xab8a, 0xab6a, 0xa329, 0xa308, 0xa329, 0xab8a, 0xb3ab, 0xb3cb, 0xb3cb, 0xa36a, 0x9308, 0x9b08, 0x9c0e, 0xd79f, 0xf7df, 0xef7e, 0xe75d, 0xe75d, 0xe73d, 0xe73d, 0xe73c, 0xe73d, 0xe75d, 0xef7d, 0xef7d, 0xef7d, 0xf79e, 0xf79d, 0xef7d, 0xef7d, 0xef7d, 0xef7d, 0xef7d, 0xe75c, 0xe73c, 0xdf1c, 0xdefc, 0xdefc, 0xd6fb, 0xef7e, 0xffff, 0xffff, 0xffff, 0xffdf, 0xf7bf, 0xf7be, 0xef9e,
		0xf7df, 0xffff, 0xffff, 0xffff, 0xffff, 0xffff, 0xffff, 0xffff, 0xffff, 0xffff, 0xffff, 0xffff, 0xffff, 0xffff, 0xffff, 0xffff, 0xffff, 0xffff, 0xefbe, 0xcefc, 0x9576, 0x534e, 0x326c, 0x3a6d, 0x322c, 0x5331, 0x428d, 0x2967, 0x2126, 0x5a07, 0xbc0c, 0xbc0c, 0xb3aa, 0xab8a, 0xab69, 0xab49, 0xab28, 0xa2e8, 0x9ae7, 0x9ac7, 0x9ae7, 0x92a7, 0x8a87, 0x92c8, 0xab8a, 0x49c6, 0x42cc, 0xbe7a, 0xcedb, 0xe77e, 0xf7bf, 0xef9e, 0xef5d, 0xe75d, 0xe73d, 0xe75d, 0xef5d, 0xef7d, 0xef7d, 0xef9d, 0xef7d, 0xef7d, 0xef7d, 0xef7d, 0xef5d, 0xef5c, 0xe73c, 0xdf1c, 0xdefc, 0xdefc, 0xd6db, 0xd6db, 0xe77e, 0xffff, 0xffff, 0xffff, 0xffdf, 0xf7df, 0xf7be, 0xf79e,
		0xffff, 0xffff, 0xffff, 0xffff, 0xffff, 0xffff, 0xffff, 0xffff, 0xffff, 0xffff, 0xffff, 0xffff, 0xffff, 0xffff, 0xf7ff, 0xd73d, 0xae19, 0x7494, 0x5370, 0x3a8d, 0x29a8, 0x2147, 0x426c, 0x428d, 0x3a2b, 0x4b10, 0x426c, 0x2966, 0x2146, 0x3166, 0x9b29, 0xb3cb, 0xab8a, 0xab49, 0xa349, 0xa329, 0xa328, 0xa308, 0xab08, 0xab08, 0xa308, 0xa2e8, 0xa308, 0xab69, 0x9b29, 0x2904, 0x10a3, 0x2987, 0x3229, 0x4aec, 0x7c51, 0xa596, 0xc69a, 0xdf3c, 0xe77d, 0xef9e, 0xf79e, 0xf79d, 0xef7d, 0xef7d, 0xef5d, 0xef5d, 0xef5c, 0xef5c, 0xe75c, 0xe73c, 0xdefc, 0xd6fc, 0xd6db, 0xd6db, 0xd6db, 0xd6db, 0xe77d, 0xffff, 0xffff, 0xffff, 0xffdf, 0xf7df, 0xf7be, 0xf79e,
		0xffff, 0xffff, 0xffff, 0xffff, 0xffff, 0xffff, 0xffff, 0xffff, 0xffff, 0xffff, 0xffff, 0xd71c, 0x9d96, 0x6c11, 0x42cc, 0x320a, 0x29a9, 0x31c9, 0x31ea, 0x29a8, 0x2988, 0x3a0a, 0x3a2b, 0x31ea, 0x31ca, 0x4aef, 0x3a0a, 0x2967, 0x2987, 0x2105, 0x6206, 0xa329, 0xa349, 0xa329, 0xa329, 0xa308, 0xa308, 0xa308, 0xa308, 0xa328, 0xab28, 0xab49, 0xab49, 0xb38a, 0x7a67, 0x18c4, 0x2105, 0x2125, 0x31c8, 0x2967, 0x2126, 0x2147, 0x31e9, 0x428b, 0x5b6e, 0x7c52, 0xa576, 0xce9a, 0xdf1c, 0xef9e, 0xf79e, 0xe73c, 0xe73c, 0xe73c, 0xe73c, 0xdf1c, 0xd6db, 0xd6db, 0xd6db, 0xd6db, 0xd6db, 0xcebb, 0xe75d, 0xffff, 0xffff, 0xffff, 0xffdf, 0xf7df, 0xf7be, 0xef9e,
		0xffff, 0xffff, 0xffff, 0xffff, 0xffff, 0xffff, 0xffff, 0xffff, 0xffff, 0xe79e, 0x7cd6, 0x3ace, 0x21a8, 0x2147, 0x2167, 0x2988, 0x31c8, 0x31c8, 0x2988, 0x29a8, 0x31e9, 0x31e9, 0x31c9, 0x31a8, 0x39ea, 0x4a8d, 0x31c9, 0x31c9, 0x2988, 0x2146, 0x3966, 0x7247, 0x9b08, 0xa329, 0x9b08, 0x9ae8, 0xa308, 0xa308, 0xa328, 0xab49, 0xab49, 0xab69, 0xb389, 0xb369, 0x6a06, 0x18e4, 0x2105, 0x2125, 0x2966, 0x31a8, 0x2967, 0x2967, 0x2946, 0x2146, 0x2146, 0x2146, 0x2967, 0x29a8, 0x3a6a, 0x6bd0, 0xadd7, 0xe75d, 0xef7d, 0xe73c, 0xe71c, 0xdefb, 0xd6db, 0xd6db, 0xd6db, 0xd6db, 0xd6bb, 0xce9a, 0xe75d, 0xffff, 0xffff, 0xffff, 0xffdf, 0xf7df, 0xf7be, 0xf79e,
		0xffff, 0xffff, 0xffff, 0xffff, 0xffff, 0xffff, 0xffff, 0xffff, 0xbe7b, 0x5392, 0x322c, 0x3a2b, 0x3a2a, 0x31c9, 0x31c8, 0x29a8, 0x2987, 0x31a8, 0x2987, 0x31a8, 0x31a8, 0x31a8, 0x2988, 0x2967, 0x31ea, 0x426c, 0x31c9, 0x3188, 0x2967, 0x2987, 0x2967, 0x2966, 0x5a06, 0x92c7, 0x92e8, 0x92c7, 0x9ae8, 0xa328, 0xab49, 0xab49, 0xab49, 0xab69, 0xb369, 0xa308, 0x61e6, 0x18e4, 0x2105, 0x2125, 0x2146, 0x2987, 0x3187, 0x2966, 0x2966, 0x2146, 0x2146, 0x2926, 0x2966, 0x2946, 0x2967, 0x2967, 0x2987, 0x52ed, 0xa576, 0xe75d, 0xef5d, 0xdf1c, 0xe73d, 0xe75d, 0xe75d, 0xe73d, 0xdf3d, 0xdf1c, 0xef9e, 0xffff, 0xffff, 0xffff, 0xffdf, 0xf7df, 0xf7be, 0xf79e,
		0xffff, 0xffff, 0xffff, 0xffff, 0xffff, 0xffff, 0xffff, 0xae1a, 0x326d, 0x31ea, 0x29a8, 0x29a8, 0x31e9, 0x31c9, 0x2987, 0x2988, 0x29a8, 0x29a8, 0x2967, 0x2987, 0x2987, 0x2987, 0x2967, 0x2987, 0x31ea, 0x3a2b, 0x31c9, 0x2967, 0x2967, 0x2967, 0x2987, 0x2147, 0x2147, 0x6a27, 0x8aa7, 0x8287, 0x8aa7, 0x9b08, 0xa328, 0xa328, 0xa328, 0xa328, 0xa328, 0x92c7, 0x61e5, 0x2104, 0x2105, 0x2125, 0x2946, 0x2946, 0x2987, 0x31a7, 0x2987, 0x2946, 0x2946, 0x2946, 0x2946, 0x2966, 0x2987, 0x2987, 0x2966, 0x2126, 0x2167, 0x530d, 0xbe79, 0xf7df, 0xf7df, 0xffff, 0xffff, 0xffdf, 0xf7df, 0xf7df, 0xffff, 0xffff, 0xffff, 0xffff, 0xffdf, 0xf7df, 0xf7be, 0xf79e,
		0xffff, 0xffff, 0xffff, 0xffff, 0xffff, 0xffff, 0xd71d, 0x4b10, 0x320b, 0x31e9, 0x2987, 0x2987, 0x2988, 0x31a8, 0x2987, 0x2147, 0x2967, 0x2146, 0x2967, 0x2987, 0x2987, 0x2987, 0x2967, 0x31a8, 0x39ea, 0x3a2a, 0x31c8, 0x2967, 0x2947, 0x2967, 0x2987, 0x2967, 0x2167, 0x3187, 0x8aa8, 0x8a87, 0x8246, 0x8a86, 0x9ac7, 0x9ac7, 0x9ac7, 0x9ae8, 0x92c7, 0x8287, 0x51a5, 0x2104, 0x2125, 0x2125, 0x2946, 0x2966, 0x2966, 0x2987, 0x3187, 0x2967, 0x2966, 0x2967, 0x2946, 0x2946, 0x2946, 0x2946, 0x2967, 0x2966, 0x2987, 0x1905, 0x322a, 0xdf3d, 0xffff, 0xffff, 0xffff, 0xffff, 0xffff, 0xffff, 0xffff, 0xffff, 0xffff, 0xffff, 0xffdf, 0xf7df, 0xf7be, 0xf79e,
		0xffff, 0xffff, 0xffff, 0xffff, 0xffff, 0xffff, 0x63f2, 0x320b, 0x31e9, 0x31c8, 0x2987, 0x2146, 0x2167, 0x2987, 0x2987, 0x2966, 0x2146, 0x2946, 0x2946, 0x2146, 0x2146, 0x2967, 0x3188, 0x31a9, 0x31c9, 0x39e9, 0x2987, 0x2966, 0x2946, 0x2967, 0x2987, 0x2987, 0x2967, 0x2147, 0x6227, 0x9ac7, 0x8246, 0x8a66, 0x92a7, 0x9ac7, 0x92a7, 0x92a7, 0x8266, 0x71e5, 0x5a07, 0x2966, 0x2105, 0x2125, 0x2946, 0x2967, 0x2967, 0x2967, 0x2967, 0x2987, 0x2967, 0x2967, 0x2946, 0x2946, 0x2966, 0x2146, 0x2966, 0x2966, 0x2967, 0x2987, 0x2967, 0x5b6e, 0xf7ff, 0xffff, 0xffff, 0xffff, 0xffff, 0xffff, 0xffff, 0xffff, 0xffff, 0xffff, 0xffdf, 0xf7df, 0xf7be, 0xef7e,
		0xffff, 0xffff, 0xffff, 0xffff, 0xffff, 0xd6fc, 0x320b, 0x320a, 0x29c9, 0x2988, 0x2987, 0x2967, 0x2146, 0x2146, 0x2987, 0x2946, 0x2126, 0x2946, 0x2967, 0x2967, 0x2125, 0x18e5, 0x18e5, 0x18e5, 0x2967, 0x31a8, 0x2946, 0x2967, 0x2946, 0x2967, 0x2987, 0x2987, 0x2967, 0x2147, 0x3167, 0x930a, 0x92a7, 0x8246, 0x8a45, 0x8a45, 0x8a25, 0x8205, 0x7a25, 0x8b4a, 0xacd1, 0x2966, 0x2125, 0x2946, 0x2946, 0x2966, 0x2967, 0x2967, 0x2967, 0x2966, 0x2966, 0x2946, 0x2126, 0x2146, 0x2966, 0x2146, 0x2946, 0x2946, 0x2966, 0x31a8, 0x31c8, 0x2126, 0x84d3, 0xffff, 0xffff, 0xffff, 0xffff, 0xffff, 0xffff, 0xffff, 0xffff, 0xf7df, 0xf7be, 0xef9e, 0xef7d, 0xe73c,
		0xffff, 0xffff, 0xffff, 0xffff, 0xffff, 0xa5b8, 0x29ca, 0x29a9, 0x29a8, 0x29a8, 0x2987, 0x2987, 0x2167, 0x1925, 0x2946, 0x2967, 0x2946, 0x2126, 0x2946, 0x2967, 0x2967, 0x2126, 0x18c4, 0x2106, 0x31c8, 0x2967, 0x2946, 0x2967, 0x2967, 0x2946, 0x2967, 0x2967, 0x2967, 0x2967, 0x2126, 0x5a8a, 0x9c2e, 0x9bed, 0xa40d, 0xac2e, 0xac4e, 0xbcb0, 0xc594, 0xde78, 0x9c91, 0x1905, 0x2146, 0x2946, 0x2946, 0x2946, 0x2967, 0x2967, 0x2967, 0x2967, 0x2946, 0x2946, 0x2146, 0x2946, 0x2105, 0x2125, 0x2966, 0x2966, 0x2967, 0x31a8, 0x3187, 0x2126, 0x3a6a, 0xf7df, 0xffff, 0xffff, 0xffff, 0xffff, 0xffff, 0xf7df, 0xef9e, 0xe77d, 0xe73c, 0xdefb, 0xe73c, 0xe73c,
		0xffff, 0xffff, 0xffff, 0xffff, 0xffff, 0x7454, 0x29a9, 0x29a8, 0x29a8, 0x2987, 0x2987, 0x2987, 0x2987, 0x2126, 0x2105, 0x2967, 0x2946, 0x2126, 0x2126, 0x2146, 0x2946, 0x2967, 0x2946, 0x3188, 0x2987, 0x2946, 0x2946, 0x2967, 0x2967, 0x2946, 0x2967, 0x2967, 0x2967, 0x2946, 0x2126, 0x3187, 0x8bee, 0xa4d1, 0xc5b5, 0xd658, 0xde98, 0xde98, 0xde78, 0xde98, 0x83ef, 0x18e5, 0x2946, 0x2946, 0x2946, 0x2946, 0x2966, 0x2967, 0x2967, 0x2967, 0x2966, 0x2966, 0x2946, 0x2946, 0x18e5, 0x2125, 0x2966, 0x2966, 0x2987, 0x2987, 0x2967, 0x2966, 0x29a8, 0xdf3d, 0xffff, 0xffdf, 0xf7df, 0xf7bf, 0xef9f, 0xef9e, 0xef7e, 0xef7e, 0xdf1c, 0xdefb, 0xef5d, 0xef5d,
		0xffff, 0xffff, 0xffff, 0xffff, 0xef9e, 0x4b30, 0x29a9, 0x29a8, 0x2187, 0x2987, 0x2967, 0x2967, 0x2967, 0x2967, 0x1905, 0x2946, 0x2946, 0x2146, 0x2126, 0x2126, 0x2946, 0x2946, 0x2946, 0x2946, 0x2967, 0x2946, 0x2946, 0x2946, 0x2967, 0x2947, 0x2947, 0x2967, 0x2946, 0x2946, 0x2946, 0x2126, 0x7b8d, 0xacd1, 0xbd53, 0xcdf6, 0xd637, 0xd657, 0xd657, 0xde78, 0x8c30, 0x1905, 0x2946, 0x2966, 0x2946, 0x2966, 0x2966, 0x2967, 0x2967, 0x2967, 0x2966, 0x2146, 0x2125, 0x2146, 0x2105, 0x2946, 0x2967, 0x2966, 0x2967, 0x2966, 0x2146, 0x2987, 0x1925, 0xa596, 0xffff, 0xef9e, 0xef9e, 0xf7bf, 0xf7df, 0xf7df, 0xf7df, 0xf7df, 0xef7d, 0xe75d, 0xf79e, 0xef7d,
		0xffff, 0xffff, 0xffff, 0xffff, 0xd6fc, 0x3a6d, 0x29a9, 0x2987, 0x2987, 0x2146, 0x2167, 0x2967, 0x2967, 0x2947, 0x2126, 0x2125, 0x2946, 0x2146, 0x2126, 0x2126, 0x2946, 0x2946, 0x2146, 0x2946, 0x2967, 0x2946, 0x2946, 0x2946, 0x2946, 0x2946, 0x2946, 0x2946, 0x2946, 0x2946, 0x2946, 0x2125, 0x5aaa, 0xa4b1, 0xb533, 0xcdf5, 0xd637, 0xd657, 0xd657, 0xde78, 0x9450, 0x1905, 0x2966, 0x2946, 0x2966, 0x2966, 0x2966, 0x2966, 0x2146, 0x2125, 0x1905, 0x10e4, 0x2125, 0x2946, 0x2105, 0x2966, 0x2967, 0x2967, 0x2966, 0x2146, 0x2987, 0x2146, 0x2126, 0x6baf, 0xffff, 0xffdf, 0xffff, 0xffff, 0xffff, 0xffff, 0xffff, 0xffff, 0xef9e, 0xef5d, 0xf79e, 0xef7e,
		0xffff, 0xffff, 0xffff, 0xffff, 0xcedc, 0x324c, 0x320a, 0x2167, 0x2967, 0x2987, 0x2146, 0x2126, 0x2146, 0x2926, 0x2126, 0x2126, 0x2946, 0x2146, 0x2126, 0x2105, 0x2126, 0x2146, 0x2146, 0x2146, 0x2946, 0x2946, 0x2946, 0x2946, 0x2946, 0x2946, 0x2946, 0x2146, 0x2946, 0x2946, 0x2946, 0x2126, 0x4208, 0x93ee, 0xa4b1, 0xc595, 0xce17, 0xd637, 0xce17, 0xd658, 0x9491, 0x2105, 0x2966, 0x2966, 0x2966, 0x2967, 0x2966, 0x2966, 0x2146, 0x18e4, 0x1905, 0x1905, 0x2946, 0x2125, 0x2125, 0x2966, 0x2966, 0x2966, 0x2146, 0x2966, 0x2966, 0x2146, 0x2987, 0x31e9, 0xd71c, 0xffff, 0xffff, 0xffff, 0xffff, 0xffff, 0xffff, 0xffff, 0xef9e, 0xe75d, 0xf79e, 0xf79e,
		0xffff, 0xffff, 0xffff, 0xffff, 0xcebb, 0x320b, 0x320a, 0x31c9, 0x2126, 0x2146, 0x2987, 0x2146, 0x2105, 0x2126, 0x2126, 0x2105, 0x2146, 0x2946, 0x2946, 0x2125, 0x2126, 0x2126, 0x2946, 0x2926, 0x2146, 0x2946, 0x2946, 0x2946, 0x2946, 0x2946, 0x2146, 0x2946, 0x2946, 0x2946, 0x2946, 0x2126, 0x39e8, 0x8bad, 0x940f, 0xb533, 0xcdf6, 0xd637, 0xcdf6, 0xd658, 0xa4d2, 0x2125, 0x2946, 0x2966, 0x2966, 0x2967, 0x2967, 0x2966, 0x2946, 0x2946, 0x2125, 0x2125, 0x2946, 0x2125, 0x2125, 0x2966, 0x2966, 0x2146, 0x2146, 0x2967, 0x2146, 0x2966, 0x2967, 0x2146, 0x7c72, 0xffff, 0xffff, 0xffff, 0xffff, 0xffff, 0xffff, 0xffff, 0xef9e, 0xe75d, 0xf79e, 0xf79e,
		0xffff, 0xffff, 0xffff, 0xffff, 0xadf9, 0x21a9, 0x320a, 0x3a0a, 0x29a8, 0x1925, 0x2146, 0x2166, 0x2126, 0x2105, 0x2926, 0x2105, 0x2105, 0x2946, 0x2126, 0x2126, 0x2105, 0x2126, 0x2126, 0x2946, 0x2126, 0x2126, 0x2946, 0x2946, 0x2946, 0x2946, 0x2146, 0x2946, 0x2946, 0x2946, 0x2946, 0x2126, 0x39c8, 0x8c0e, 0x8bee, 0xa4b1, 0xc5b5, 0xce17, 0xcdf6, 0xce37, 0xb574, 0x2986, 0x2146, 0x2966, 0x2966, 0x2966, 0x2966, 0x2966, 0x2946, 0x2946, 0x2946, 0x2125, 0x2146, 0x2125, 0x2125, 0x2967, 0x2946, 0x2105, 0x2967, 0x2146, 0x2146, 0x2967, 0x2146, 0x2987, 0x428b, 0xe79e, 0xef9e, 0xef9e, 0xef9e, 0xffff, 0xffff, 0xffff, 0xf7bf, 0xef7d, 0xef9e, 0xf79e,
		0xefbf, 0xefbe, 0xf7bf, 0xffff, 0x9537, 0x2188, 0x31c9, 0x31e9, 0x31c8, 0x2967, 0x1925, 0x2126, 0x2946, 0x2126, 0x2105, 0x2125, 0x20e5, 0x2926, 0x2126, 0x2946, 0x2125, 0x2105, 0x2126, 0x2126, 0x2926, 0x2945, 0x2126, 0x2126, 0x2946, 0x2146, 0x2946, 0x2946, 0x2946, 0x2946, 0x2946, 0x2126, 0x3187, 0x944f, 0x9c4f, 0x9c70, 0xb553, 0xce16, 0xce17, 0xd658, 0xa4d2, 0x2125, 0x2946, 0x2966, 0x2966, 0x2966, 0x2967, 0x2966, 0x2946, 0x2946, 0x2946, 0x2125, 0x2946, 0x2125, 0x2146, 0x2966, 0x2105, 0x2126, 0x2966, 0x2146, 0x2966, 0x2126, 0x2966, 0x31c8, 0x31a8, 0xc659, 0xdf1c, 0xdf1c, 0xef9e, 0xffff, 0xffff, 0xffff, 0xffdf, 0xef7e, 0xe75d, 0xe71c,
		0xd6fb, 0xdf1c, 0xef9e, 0xffff, 0x7c75, 0x29a9, 0x2167, 0x29a8, 0x29a8, 0x2987, 0x2967, 0x2105, 0x2105, 0x2946, 0x2126, 0x2105, 0x18c4, 0x2105, 0x2146, 0x2126, 0x2126, 0x2105, 0x2125, 0x2126, 0x2926, 0x7a25, 0x2125, 0x2126, 0x2125, 0x2126, 0x2126, 0x2146, 0x2926, 0x2926, 0x2946, 0x2126, 0x2126, 0x8c0f, 0xa4b1, 0x9c50, 0xacf2, 0xc5d5, 0xce17, 0xd658, 0x9cb2, 0x2105, 0x2946, 0x2966, 0x2946, 0x2966, 0x2967, 0x2967, 0x2946, 0x2946, 0x2125, 0x2105, 0x2946, 0x2125, 0x2946, 0x2946, 0x1904, 0x2946, 0x2946, 0x2946, 0x2126, 0x2125, 0x2987, 0x31a7, 0x2146, 0xb5d7, 0xffdf, 0xf7be, 0xffff, 0xffff, 0xffff, 0xffff, 0xf7be, 0xe71b, 0xd679, 0xce17,
		0xadb6, 0xce9a, 0xef9e, 0xef9e, 0x5bb3, 0x3a4c, 0x2146, 0x2987, 0x29a8, 0x2987, 0x2167, 0x2967, 0x2126, 0x2105, 0x2126, 0x2946, 0x2105, 0x18e4, 0x2126, 0x2126, 0x2126, 0x2126, 0x2105, 0x2105, 0x2945, 0x9ac4, 0x3945, 0x1905, 0x2125, 0x2126, 0x2126, 0x2126, 0x2126, 0x2146, 0x2146, 0x2146, 0x18e5, 0x734d, 0xb513, 0x9c90, 0xa4b1, 0xb554, 0xce17, 0xce37, 0xa4d2, 0x39c7, 0x2946, 0x2946, 0x2946, 0x2966, 0x2966, 0x2966, 0x2966, 0x2946, 0x2125, 0x2125, 0x2946, 0x2125, 0x2946, 0x2125, 0x1905, 0x2966, 0x2966, 0x2146, 0x2105, 0x2946, 0x3187, 0x2987, 0x2967, 0x426b, 0xef7d, 0xffff, 0xffff, 0xffff, 0xf7be, 0xef3c, 0xdeb9, 0xd637, 0xce16, 0xcdd5,
		0xad95, 0xce9a, 0xf7be, 0xdf1d, 0x4b11, 0x4acf, 0x2147, 0x2146, 0x2987, 0x2987, 0x2167, 0x2947, 0x2947, 0x2126, 0x2105, 0x2126, 0x2926, 0x2105, 0x2105, 0x2126, 0x2126, 0x2126, 0x2126, 0x1905, 0x2925, 0x9244, 0x9203, 0x2105, 0x2126, 0x2126, 0x2126, 0x2126, 0x2126, 0x2126, 0x2946, 0x2126, 0x18e5, 0x528a, 0xb553, 0xacf2, 0xa4d2, 0xacf2, 0xc5b5, 0xce17, 0xcdf6, 0x7bae, 0x2125, 0x2946, 0x2946, 0x2946, 0x2966, 0x2966, 0x2966, 0x2946, 0x2926, 0x2125, 0x2946, 0x2105, 0x2946, 0x2105, 0x2125, 0x2946, 0x2146, 0x2105, 0x2125, 0x2966, 0x2966, 0x2967, 0x31a8, 0x1906, 0xb5f8, 0xffff, 0xef5c, 0xe6fa, 0xd678, 0xd636, 0xd616, 0xd616, 0xd616, 0xcdf5,
		0xadb6, 0xceba, 0xf7df, 0xcebb, 0x42d0, 0x4ad0, 0x31c9, 0x2146, 0x2147, 0x2967, 0x2967, 0x2146, 0x2946, 0x2946, 0x2126, 0x2105, 0x2105, 0x2126, 0x18e5, 0x2125, 0x2926, 0x3925, 0x3925, 0x3125, 0x28e5, 0x4145, 0x79a4, 0x3925, 0x2126, 0x2126, 0x2126, 0x2126, 0x2126, 0x2126, 0x2126, 0x2126, 0x2105, 0x39e8, 0xb553, 0xacf3, 0x9c91, 0x9c91, 0xb534, 0xcdf6, 0xce37, 0x942f, 0x2966, 0x2146, 0x2946, 0x2946, 0x2946, 0x2966, 0x2966, 0x2946, 0x2125, 0x2125, 0x2946, 0x2105, 0x2946, 0x20e5, 0x2926, 0x2946, 0x2105, 0x2105, 0x2946, 0x2946, 0x2946, 0x3167, 0x31a8, 0x1905, 0x7bf0, 0xef1a, 0xd657, 0xd636, 0xd636, 0xd637, 0xd637, 0xd636, 0xd616, 0xcdf5,
		0xadb6, 0xceba, 0xf7df, 0xbe5a, 0x42af, 0x42ae, 0x320a, 0x2967, 0x2146, 0x2146, 0x2967, 0x2946, 0x2946, 0x2946, 0x2926, 0x2126, 0x2105, 0x2105, 0x18e5, 0x18e5, 0x3925, 0x7944, 0x8163, 0x6944, 0x7144, 0x6923, 0x6924, 0x4904, 0x2126, 0x2126, 0x2126, 0x2125, 0x2126, 0x2126, 0x2126, 0x2126, 0x2125, 0x2946, 0xa4d2, 0x9c91, 0xa4f2, 0xa4f2, 0x9471, 0xbdb5, 0xce17, 0x9c91, 0x39a7, 0x2125, 0x2946, 0x2946, 0x2146, 0x2966, 0x2966, 0x2966, 0x2946, 0x2126, 0x2125, 0x18e4, 0x2125, 0x18e4, 0x2126, 0x2125, 0x2105, 0x2926, 0x2946, 0x2146, 0x2126, 0x3187, 0x3187, 0x2105, 0x4a8b, 0xde57, 0xde57, 0xde57, 0xd657, 0xd637, 0xd637, 0xd637, 0xd616, 0xcdf5,
		0xadb7, 0xceba, 0xffff, 0xb61a, 0x42af, 0x426d, 0x320a, 0x29a8, 0x2987, 0x2146, 0x2946, 0x2946, 0x2946, 0x2946, 0x2926, 0x2126, 0x2146, 0x2105, 0x20e5, 0x18c4, 0x6944, 0x5144, 0x7144, 0x7123, 0x7123, 0x6923, 0x6923, 0x7123, 0x20e5, 0x2126, 0x2126, 0x2105, 0x2125, 0x2126, 0x2126, 0x2126, 0x2126, 0x18e5, 0x9450, 0xad13, 0x83ef, 0x5aeb, 0x5acb, 0x9cb2, 0xce17, 0xad12, 0x4a28, 0x2105, 0x2946, 0x2946, 0x2946, 0x2946, 0x2946, 0x2946, 0x2966, 0x2946, 0x18e4, 0x18c4, 0x2105, 0x18e4, 0x2105, 0x2105, 0x2125, 0x2946, 0x2926, 0x2126, 0x2966, 0x3187, 0x2946, 0x2126, 0x31a8, 0xbdb5, 0xe698, 0xde57, 0xd657, 0xd657, 0xd637, 0xd637, 0xd616, 0xcdd5,
		0xadb6, 0xceba, 0xffff, 0xb5d9, 0x42af, 0x3a4c, 0x31ea, 0x29a8, 0x2987, 0x2967, 0x2947, 0x2947, 0x2946, 0x2946, 0x2946, 0x2146, 0x2126, 0x2126, 0x2126, 0x20e5, 0x20e4, 0x18c4, 0x51e5, 0x7aa5, 0x7285, 0x7244, 0x7a44, 0x6204, 0x5204, 0x2105, 0x2105, 0x2105, 0x2105, 0x2125, 0x2126, 0x2126, 0x2126, 0x18c4, 0x6b4d, 0xcdd5, 0x9430, 0x52ab, 0x7bae, 0x630c, 0xcdf7, 0xb554, 0x5aaa, 0x1905, 0x2946, 0x2946, 0x2946, 0x2946, 0x2946, 0x2946, 0x2946, 0x2946, 0x18e4, 0x18c4, 0x18e4, 0x20e4, 0x18e4, 0x2125, 0x2126, 0x2926, 0x2105, 0x2946, 0x2967, 0x2946, 0x2125, 0x2946, 0x2967, 0xa4f3, 0xe6b9, 0xde57, 0xde57, 0xd657, 0xd637, 0xd616, 0xcdf5, 0xc5b4,
		0xadb7, 0xceba, 0xffff, 0xadb8, 0x42af, 0x424c, 0x31c9, 0x29a8, 0x2967, 0x2947, 0x2967, 0x2947, 0x2967, 0x2947, 0x2946, 0x2946, 0x2926, 0x2126, 0x2126, 0x2125, 0x18e5, 0x18c4, 0x2904, 0x3985, 0x3985, 0x3185, 0x39a5, 0x3985, 0x39a5, 0x1905, 0x18e5, 0x2105, 0x2105, 0x2105, 0x2125, 0x2125, 0x2126, 0x18e5, 0x4a29, 0xc5b5, 0x7b8e, 0x39c8, 0x4209, 0x736d, 0xc5d6, 0xbd74, 0x6b0c, 0x18e5, 0x2926, 0x2926, 0x2946, 0x2946, 0x2946, 0x2126, 0x2926, 0x2946, 0x18c4, 0x18c3, 0x18c4, 0x18e4, 0x18e4, 0x2125, 0x2126, 0x2105, 0x2126, 0x2946, 0x2946, 0x2125, 0x2125, 0x2967, 0x2967, 0x8430, 0xe6d9, 0xde78, 0xd657, 0xd637, 0xd616, 0xcdf5, 0xc5b4, 0xbd53,
		0xb5f8, 0xcebb, 0xffff, 0xa578, 0x428f, 0x3a2c, 0x29a9, 0x2988, 0x2967, 0x2947, 0x2947, 0x2946, 0x2946, 0x2946, 0x2126, 0x2126, 0x2126, 0x2125, 0x2125, 0x2125, 0x2105, 0x20e5, 0x18c4, 0x1084, 0x18e5, 0x2105, 0x18e5, 0x20e5, 0x18e5, 0x1905, 0x2105, 0x2105, 0x2105, 0x2105, 0x2125, 0x2125, 0x2125, 0x2105, 0x2946, 0xb533, 0x8c0f, 0x6b2c, 0x736d, 0x5acb, 0xbd95, 0xbd94, 0x7b8d, 0x20e5, 0x2926, 0x2925, 0x2126, 0x2126, 0x2125, 0x2125, 0x2105, 0x2105, 0x18c4, 0x18a3, 0x18a3, 0x18e4, 0x18e4, 0x2105, 0x2105, 0x2105, 0x2946, 0x2926, 0x2125, 0x2125, 0x2946, 0x2967, 0x2967, 0x5b0d, 0xde78, 0xd657, 0xd637, 0xce16, 0xcdd5, 0xc594, 0xbd53, 0xbd32,
		0xbe38, 0xd6fc, 0xffff, 0xa578, 0x428f, 0x3a0b, 0x2987, 0x2126, 0x2146, 0x2947, 0x2947, 0x2946, 0x2946, 0x2946, 0x2126, 0x2125, 0x2126, 0x2126, 0x2125, 0x2125, 0x2125, 0x20e5, 0x20e5, 0x18c4, 0x18a3, 0x20e5, 0x2105, 0x2105, 0x2105, 0x1905, 0x1905, 0x2105, 0x1905, 0x2105, 0x2105, 0x2125, 0x2125, 0x2125, 0x18e4, 0x8c0f, 0x8c30, 0x3a08, 0x4a49, 0x7bce, 0xbd74, 0xbd94, 0x8bee, 0x2105, 0x2125, 0x2125, 0x2126, 0x2125, 0x2125, 0x2125, 0x2105, 0x20e4, 0x18e4, 0x10a3, 0x18c3, 0x18e4, 0x18c4, 0x18e4, 0x2105, 0x2946, 0x2926, 0x2126, 0x2926, 0x2926, 0x2946, 0x2967, 0x2967, 0x31c8, 0xb574, 0xde57, 0xcdd5, 0xc5b4, 0xc573, 0xbd53, 0xbd53, 0xc594,
		0xef9e, 0xffff, 0xffff, 0xadb8, 0x3a8f, 0x39ea, 0x2a0a, 0x3b2f, 0x29a8, 0x2126, 0x2947, 0x2946, 0x2946, 0x2946, 0x2126, 0x2125, 0x2125, 0x2125, 0x2125, 0x2125, 0x2125, 0x2105, 0x18c4, 0x20e5, 0x18c4, 0x18a3, 0x20e5, 0x2105, 0x2105, 0x2105, 0x18e4, 0x1905, 0x1905, 0x2105, 0x2105, 0x2125, 0x2125, 0x2125, 0x18e4, 0x5289, 0xbd74, 0x842f, 0x8c0f, 0xb553, 0xb533, 0xbd74, 0x9450, 0x2945, 0x18e4, 0x2105, 0x2105, 0x2105, 0x18e4, 0x2105, 0x2105, 0x18e4, 0x3144, 0x3145, 0x2105, 0x2104, 0x18c4, 0x2125, 0x2126, 0x2125, 0x2125, 0x2126, 0x2126, 0x2126, 0x2946, 0x3187, 0x2966, 0x2146, 0x8410, 0xd615, 0xc573, 0xbd53, 0xbd73, 0xc594, 0xc5f6, 0xce38,
		0xf7be, 0xe73c, 0xe6fa, 0x94d4, 0x6b6f, 0x9410, 0x6c53, 0x4b70, 0x224b, 0x2106, 0x2947, 0x2946, 0x2946, 0x2146, 0x2126, 0x2126, 0x2125, 0x2125, 0x2125, 0x2125, 0x2125, 0x2105, 0x18a3, 0x18a3, 0x18e4, 0x18c4, 0x18a4, 0x2105, 0x2105, 0x2105, 0x18e4, 0x18e4, 0x2105, 0x2105, 0x2105, 0x2125, 0x2125, 0x2125, 0x2105, 0x3186, 0xacd1, 0xc5b5, 0xb512, 0xad12, 0xad13, 0xb554, 0x9c91, 0x3186, 0x18c4, 0x18e4, 0x18c4, 0x10a3, 0x10a3, 0x10a3, 0x10a3, 0x1083, 0x20e3, 0x4164, 0x4184, 0x2903, 0x2105, 0x2126, 0x2126, 0x2105, 0x2105, 0x2125, 0x2125, 0x2926, 0x2967, 0x2967, 0x2946, 0x2146, 0x5acb, 0xc594, 0xc573, 0xc5b4, 0xcdf6, 0xce58, 0xd69a, 0xdedb,
		0xc5f6, 0xc5b5, 0xd658, 0x94d5, 0xa556, 0xbd34, 0x8c12, 0x4a6c, 0x3aac, 0x49c4, 0x3966, 0x2146, 0x2146, 0x2126, 0x2126, 0x2125, 0x2125, 0x2125, 0x2125, 0x2125, 0x2125, 0x2125, 0x10a3, 0x0862, 0x10a3, 0x18c4, 0x18a3, 0x18c4, 0x2105, 0x2105, 0x2105, 0x18e4, 0x2105, 0x2105, 0x2105, 0x2105, 0x2105, 0x2105, 0x2105, 0x2105, 0x83ad, 0xc5b5, 0xacf2, 0xa4b1, 0xa4d2, 0xa4f2, 0x9450, 0x39a6, 0x0883, 0x10a4, 0x2924, 0x59c5, 0x7226, 0x61e5, 0x4985, 0x3144, 0x18c3, 0x0863, 0x10a3, 0x10a4, 0x2105, 0x2105, 0x2105, 0x2105, 0x2105, 0x2926, 0x2926, 0x2926, 0x2946, 0x2966, 0x2946, 0x2967, 0x39e9, 0xb553, 0xd616, 0xce58, 0xd69a, 0xdedb, 0xe71c, 0xef5d,
		0xce58, 0xdeda, 0xf7df, 0xb61a, 0xacf4, 0x8c32, 0x9c10, 0x6c55, 0x326e, 0x51c4, 0x41c6, 0x2127, 0x2126, 0x2126, 0x2126, 0x2125, 0x2105, 0x2105, 0x2105, 0x2125, 0x2125, 0x2105, 0x20e4, 0x3104, 0x28e4, 0x1083, 0x18a4, 0x18a3, 0x18c4, 0x2105, 0x2105, 0x18e4, 0x18e4, 0x2105, 0x1904, 0x1905, 0x1905, 0x2105, 0x2105, 0x18e4, 0x5aa9, 0xb553, 0xb553, 0x9c70, 0x942f, 0x8bee, 0x8c2f, 0x4a07, 0x3944, 0x7246, 0x92c7, 0xa308, 0xa328, 0xa328, 0xa328, 0x92e8, 0x6a47, 0x41a6, 0x18a3, 0x10a3, 0x2105, 0x2105, 0x20e5, 0x18e4, 0x2105, 0x2926, 0x2926, 0x2926, 0x2946, 0x2946, 0x2946, 0x2946, 0x2988, 0x9cf3, 0xe6fb, 0xdedb, 0xe71c, 0xef5d, 0xef9e, 0xf7be,
		0xd6ba, 0xdf3c, 0xf7ff, 0xce7b, 0xc38a, 0xbb49, 0xc327, 0x424a, 0x4a27, 0x41a6, 0x2126, 0x2126, 0x2126, 0x2126, 0x2125, 0x2125, 0x2105, 0x2105, 0x2105, 0x2105, 0x2105, 0x1905, 0x2925, 0x7a87, 0x82a8, 0x4165, 0x1083, 0x1083, 0x10a3, 0x18c4, 0x1904, 0x18e5, 0x18c4, 0x18c4, 0x18e4, 0x18e4, 0x18e4, 0x1905, 0x2105, 0x18c4, 0x39c7, 0x9c70, 0xb554, 0x9c90, 0x83ce, 0x5269, 0x72a9, 0x9308, 0xa307, 0xa308, 0xa308, 0xab28, 0xab48, 0xa328, 0xa348, 0xab69, 0x9ae8, 0x7a87, 0x5a27, 0x20c3, 0x18c4, 0x2105, 0x18e4, 0x2105, 0x2125, 0x2125, 0x2126, 0x2126, 0x2946, 0x2946, 0x2946, 0x2126, 0x2126, 0x73d0, 0xef7d, 0xef5d, 0xf79e, 0xf7be, 0xf7be, 0xf7be,
		0xdf3d, 0xe77e, 0xf7ff, 0xce7b, 0xbb28, 0xdbc7, 0x6a45, 0x3984, 0x2946, 0x2147, 0x2146, 0x2946, 0x2946, 0x2126, 0x2125, 0x2125, 0x2105, 0x2105, 0x2105, 0x2105, 0x2105, 0x2105, 0x18e5, 0x51c6, 0x8aa7, 0x8287, 0x59c5, 0x20c3, 0x1062, 0x10a3, 0x18c4, 0x18e4, 0x18c4, 0x18c4, 0x18e4, 0x18c4, 0x18c4, 0x18e4, 0x18e4, 0x18c4, 0x2925, 0x7b8d, 0xa4f2, 0x9c4f, 0x8309, 0x8aa7, 0xa2e7, 0xa328, 0xa308, 0xa328, 0xa328, 0xab28, 0xab48, 0xb389, 0xab49, 0xab69, 0xb3aa, 0x92e8, 0x7a87, 0x3965, 0x1083, 0x18e4, 0x2105, 0x2125, 0x2125, 0x2125, 0x2125, 0x2126, 0x2926, 0x2946, 0x2926, 0x2126, 0x20e5, 0x52ac, 0xef7d, 0xf7be, 0xf7be, 0xf7be, 0xf7be, 0xf7be,
		0xef9e, 0xf7be, 0xffff, 0xdeb9, 0x72e9, 0x4a28, 0x1927, 0x2126, 0x2146, 0x2146, 0x2146, 0x2126, 0x2126, 0x2126, 0x2125, 0x2105, 0x2105, 0x2105, 0x2105, 0x2105, 0x2105, 0x2105, 0x18e5, 0x3945, 0x7a67, 0x8287, 0x8287, 0x6a26, 0x3924, 0x1082, 0x1083, 0x18c4, 0x18c4, 0x10c4, 0x18c4, 0x18c3, 0x18c3, 0x18c4, 0x18c4, 0x10a3, 0x10c3, 0x62a9, 0x936b, 0x9ae8, 0xa2e7, 0xab28, 0xa328, 0xa328, 0xa328, 0xab48, 0xab48, 0xab28, 0xab49, 0xb3aa, 0xb3aa, 0xb3cb, 0xbbcb, 0xabaa, 0x8ae8, 0x49c6, 0x10a3, 0x2105, 0x2105, 0x2105, 0x2105, 0x2105, 0x2125, 0x2126, 0x2926, 0x2926, 0x2125, 0x2125, 0x2125, 0x3187, 0xd6db, 0xffff, 0xf7be, 0xf7be, 0xf7be, 0xf79e,
		0xf7bf, 0xf7bf, 0xffff, 0xbdf8, 0x3a0a, 0x2168, 0x2147, 0x2967, 0x2967, 0x2147, 0x2146, 0x2946, 0x2126, 0x2126, 0x2125, 0x2105, 0x2105, 0x2105, 0x2105, 0x2105, 0x2105, 0x2105, 0x18e5, 0x3965, 0x7a46, 0x7a46, 0x7a66, 0x8267, 0x7a67, 0x4984, 0x1082, 0x0883, 0x10a3, 0x10a3, 0x10a3, 0x10a3, 0x1083, 0x0883, 0x0883, 0x2904, 0x6a06, 0x92c7, 0xa2c7, 0xa328, 0xa328, 0xab28, 0xab28, 0xab28, 0xab28, 0xab48, 0xab28, 0xab48, 0xab69, 0xb38a, 0xbbcb, 0xb3aa, 0xa349, 0xa349, 0x8ac8, 0x3945, 0x18e5, 0x20e5, 0x20e5, 0x20e5, 0x20e5, 0x20e5, 0x2105, 0x2125, 0x2125, 0x2125, 0x2125, 0x2125, 0x2126, 0x18e5, 0x9cd4, 0xffff, 0xf7be, 0xf7be, 0xef7d, 0xdeda,
		0xf7bf, 0xf7bf, 0xffff, 0xa578, 0x2169, 0x41e7, 0x41c6, 0x2126, 0x2126, 0x2126, 0x2126, 0x2946, 0x2126, 0x2105, 0x2105, 0x2105, 0x2105, 0x2105, 0x2105, 0x2105, 0x2105, 0x2105, 0x18e5, 0x3944, 0x61c5, 0x61e5, 0x7226, 0x7a46, 0x7a46, 0x7a46, 0x59c5, 0x3103, 0x1082, 0x0882, 0x0862, 0x0862, 0x10a3, 0x3924, 0x6a05, 0x92c7, 0xa307, 0xa308, 0xa328, 0xa328, 0xab48, 0xab48, 0xab48, 0xab48, 0xab48, 0xab48, 0xab48, 0xb369, 0xbbaa, 0xab69, 0x9ae8, 0x92c7, 0x9b08, 0x9b08, 0x7267, 0x20e4, 0x18c4, 0x18e4, 0x18e4, 0x18e4, 0x18e4, 0x18e4, 0x18e4, 0x20e4, 0x2105, 0x2125, 0x2926, 0x2125, 0x2126, 0x2105, 0x5acc, 0xffff, 0xf7be, 0xe73c, 0xd678, 0xcdb5,
		0xf7bf, 0xf7bf, 0xffff, 0xa577, 0x72a5, 0x9365, 0x6245, 0x2946, 0x2126, 0x2126, 0x2146, 0x2946, 0x2126, 0x2105, 0x2105, 0x2105, 0x2105, 0x2105, 0x2105, 0x2105, 0x2105, 0x2105, 0x18e5, 0x3924, 0x5184, 0x59a4, 0x61e5, 0x7226, 0x7226, 0x7226, 0x7a26, 0x7226, 0x51a4, 0x3123, 0x3924, 0x59c5, 0x8286, 0xa307, 0xa328, 0xa328, 0xa328, 0xa328, 0xab48, 0xa348, 0xab48, 0xab48, 0xab48, 0xab48, 0xab48, 0xab69, 0xb369, 0xb389, 0x8287, 0x5184, 0x61c5, 0x8267, 0x8ac8, 0x8ae9, 0x41a6, 0x18a4, 0x20e4, 0x2105, 0x18e5, 0x20e5, 0x18e5, 0x18e5, 0x18e5, 0x18e4, 0x2105, 0x2105, 0x2126, 0x2126, 0x2926, 0x2126, 0x39e9, 0xdedb, 0xe6fa, 0xcdf6, 0xcdb4, 0xcdb4,
		0xf7bf, 0xf7bf, 0xffff, 0xa536, 0x41e7, 0x31a8, 0x2147, 0x2946, 0x2126, 0x2126, 0x2126, 0x2106, 0x1905, 0x2105, 0x20e5, 0x20e5, 0x18e5, 0x18e5, 0x18e5, 0x18e5, 0x18e5, 0x1905, 0x18e4, 0x3944, 0x5184, 0x59a4, 0x61c5, 0x69e5, 0x69e5, 0x7205, 0x7a25, 0x8246, 0x8a86, 0x92a7, 0x9ae7, 0xa307, 0xa308, 0xa328, 0xa328, 0xa328, 0xa328, 0xa328, 0xab48, 0xab48, 0xab49, 0xab49, 0xab48, 0xab49, 0xab69, 0xb369, 0xb369, 0x6a06, 0x1082, 0x0842, 0x1882, 0x4144, 0x69e6, 0x61e6, 0x28e4, 0x18e4, 0x20e5, 0x20e5, 0x20e5, 0x20e5, 0x20e5, 0x20e5, 0x2105, 0x2105, 0x2105, 0x2105, 0x2105, 0x2125, 0x2126, 0x2926, 0x2106, 0x83f0, 0xde16, 0xcd94, 0xcdb4, 0xcdb4,
		0xf7bf, 0xef9e, 0xffff, 0x94d5, 0x1907, 0x2146, 0x2126, 0x18e5, 0x2925, 0x4165, 0x4985, 0x51a6, 0x59e6, 0x6206, 0x6a26, 0x7226, 0x7226, 0x6a26, 0x61e6, 0x51a5, 0x3944, 0x20c4, 0x18c4, 0x4144, 0x59a4, 0x69e5, 0x7205, 0x7a45, 0x8266, 0x8aa7, 0x92c7, 0x9ae7, 0xa308, 0xa308, 0xa328, 0xa308, 0xa307, 0xa328, 0xa328, 0xa308, 0xa328, 0xa348, 0xab48, 0xab49, 0xab49, 0xab49, 0xab49, 0xab49, 0xab49, 0xab48, 0x82a8, 0x20e4, 0x1062, 0x1083, 0x1082, 0x0862, 0x1882, 0x28e3, 0x20c4, 0x18e4, 0x20e5, 0x20e5, 0x20e5, 0x1905, 0x2105, 0x2105, 0x2105, 0x2105, 0x2105, 0x2105, 0x2105, 0x2125, 0x2125, 0x2125, 0x2105, 0x4a49, 0xd594, 0xcd94, 0xcd94, 0xcd94,
		0xf7bf, 0xefbe, 0xf7ff, 0x8411, 0x0863, 0x10a3, 0x1083, 0x0862, 0x3944, 0x7246, 0x82a7, 0x92e8, 0x9b08, 0xa308, 0xa308, 0xa308, 0xa2e7, 0x9ac7, 0x9ac7, 0x9286, 0x7205, 0x59a4, 0x6a05, 0x8266, 0x9286, 0x92a7, 0x9ac7, 0x9ac7, 0x9ae7, 0xa307, 0xa307, 0xa308, 0xa328, 0xa328, 0xa328, 0xa328, 0xa328, 0xa328, 0xa328, 0xa328, 0xab48, 0xab48, 0xab49, 0xab69, 0xab49, 0xab69, 0xab69, 0xab28, 0xab49, 0x8309, 0x5289, 0x4a08, 0x1082, 0x1083, 0x1082, 0x1082, 0x1062, 0x0862, 0x18a3, 0x18c4, 0x20e5, 0x2105, 0x2105, 0x2105, 0x2105, 0x2105, 0x2105, 0x2105, 0x2105, 0x2105, 0x2105, 0x2926, 0x2105, 0x2105, 0x2926, 0x2126, 0xa491, 0xd5b4, 0xcd73, 0xcd73,
		0xf7bf, 0xf7bf, 0xf7ff, 0x7c10, 0x0821, 0x10a3, 0x1083, 0x0862, 0x2904, 0x8aa8, 0x9b09, 0xa349, 0xa329, 0xa308, 0xa308, 0x9ae7, 0x9ac7, 0x92a7, 0x9286, 0x8a66, 0x8266, 0x9286, 0x9aa7, 0x9ac7, 0x9ac7, 0x9ac7, 0x9ac7, 0x9ae7, 0x9ac7, 0x9ae7, 0xa2e7, 0xa2e7, 0xa307, 0xa307, 0xa328, 0xa328, 0xa328, 0xa328, 0xa328, 0xa348, 0xab48, 0xab48, 0xab48, 0xab69, 0xab49, 0xab49, 0xb369, 0xab69, 0x7a46, 0x5a68, 0x6289, 0x5a89, 0x2904, 0x1062, 0x1082, 0x1082, 0x1882, 0x18a2, 0x18c3, 0x18c3, 0x18a3, 0x18c4, 0x18c5, 0x2105, 0x2105, 0x2105, 0x2105, 0x2105, 0x2105, 0x2105, 0x2105, 0x2105, 0x2105, 0x2105, 0x2126, 0x2925, 0x6b0b, 0xd5b4, 0xc553, 0xc533,
		0xf7bf, 0xf7df, 0xffff, 0xbdb7, 0x0821, 0x10a3, 0x10a3, 0x1083, 0x18a3, 0x82c8, 0xa349, 0xa349, 0xa329, 0xa308, 0x9ae8, 0x9ae7, 0x9ac7, 0x9aa7, 0x9286, 0x9286, 0x92a6, 0x92a7, 0x9aa7, 0x9ac7, 0x9ac7, 0x9ac7, 0x9ac7, 0x9ac7, 0x9ae7, 0x9ae7, 0x9ae7, 0x9ae7, 0xa307, 0xa307, 0xa308, 0xa328, 0xa328, 0xa328, 0xa328, 0xa328, 0xa328, 0xa328, 0xab48, 0xab48, 0xab49, 0xab8a, 0xab69, 0x8266, 0x69c4, 0x69e4, 0x7205, 0x7205, 0x6a05, 0x69c4, 0x69e5, 0x69e5, 0x69e5, 0x7205, 0x7205, 0x69e5, 0x69c5, 0x59a4, 0x4144, 0x20c4, 0x18e5, 0x2105, 0x2105, 0x2105, 0x2105, 0x2105, 0x2105, 0x2105, 0x2105, 0x2105, 0x1906, 0x41a5, 0x7ae6, 0xc533, 0xc553, 0xac90,
		0xffff, 0xffff, 0xffff, 0xffff, 0x8410, 0x0842, 0x0021, 0x0021, 0x0001, 0x6227, 0xb3aa, 0xa349, 0xa329, 0xa308, 0x9ae8, 0x9ac7, 0x9ac7, 0x9aa7, 0x92a7, 0x92a7, 0x9286, 0x92a7, 0x9aa7, 0x9ac7, 0x9ac7, 0x9ac7, 0x9ac7, 0x9ac7, 0x9ac7, 0x9ae7, 0x9ac7, 0x9ae7, 0xa307, 0xa308, 0xa2e8, 0xa308, 0xa308, 0xa328, 0xa328, 0xa328, 0xa328, 0xa328, 0xab48, 0xab49, 0xab89, 0xa349, 0x8266, 0x7a25, 0x8266, 0x8a86, 0x8a86, 0x8a86, 0x8a86, 0x9286, 0x8a86, 0x8a86, 0x8a86, 0x8a86, 0x8a86, 0x8a86, 0x8a86, 0x92a6, 0x9286, 0x71e5, 0x3104, 0x18c4, 0x18e5, 0x18e5, 0x18e5, 0x18e5, 0x18e5, 0x18e5, 0x18e5, 0x1905, 0x2105, 0x2126, 0x2925, 0x93ef, 0xb4d0, 0x9bec,
		0xffff, 0xffff, 0xffff, 0xffff, 0xffff, 0xbdf8, 0x8c71, 0x736e, 0x5a8a, 0x838d, 0xabcb, 0xa349, 0xa349, 0xa308, 0x9ae8, 0x9ac7, 0x9ac7, 0x9ac7, 0x9ac7, 0x92a7, 0x92a7, 0x9ac7, 0x9aa7, 0x92a7, 0x92a7, 0x92a7, 0x9aa7, 0x9ac7, 0x9ac7, 0x9ae7, 0x9ae7, 0x9ae7, 0x9ae7, 0xa308, 0xa308, 0xa307, 0xa308, 0xa328, 0xa328, 0xa328, 0xa328, 0xab28, 0xab49, 0xab69, 0x9ae8, 0x7a25, 0x7205, 0x8246, 0x8266, 0x8a86, 0x92a6, 0x92a7, 0x92a7, 0x92a7, 0x92a6, 0x92a7, 0x9286, 0x8a86, 0x8a86, 0x8a86, 0x8a86, 0x9286, 0x9286, 0x9286, 0x8266, 0x59a5, 0x5185, 0x4985, 0x4985, 0x4985, 0x4985, 0x4185, 0x4165, 0x4185, 0x3145, 0x20e4, 0x10a4, 0x4a29, 0xacb0, 0xa46e,
		0xffff, 0xffff, 0xffff, 0xf7de, 0xe73c, 0xe6fa, 0xde77, 0xd636, 0xd616, 0xd5f5, 0xac2d, 0xa349, 0xa349, 0xa329, 0x9ae8, 0x9ac7, 0x92a7, 0x9ac7, 0x9ac7, 0x92c7, 0x92c7, 0x9ac7, 0x9ac7, 0x9aa7, 0x92a7, 0x92a7, 0x9ac7, 0x9ac7, 0x9ac7, 0x9ae7, 0x9ae7, 0x9ae7, 0x9ae7, 0xa2e7, 0xa308, 0xa307, 0xa308, 0xa308, 0xa308, 0xa328, 0xab48, 0xab69, 0xa349, 0x8a87, 0x7205, 0x7a25, 0x7a46, 0x8266, 0x8266, 0x8a87, 0x8a86, 0x9286, 0x8aa6, 0x92a7, 0x92a7, 0x92a7, 0x92a7, 0x92a7, 0x9287, 0x9286, 0x8a86, 0x8a86, 0x9286, 0x9286, 0x8a86, 0x9286, 0x8a86, 0x8a86, 0x8a86, 0x92a7, 0x92a7, 0x92c7, 0x9ac7, 0x9b08, 0x7a67, 0x0801, 0x1062, 0x734c, 0xc573, 0xb511,
		0xffdf, 0xef5d, 0xd699, 0xc5f6, 0xc594, 0xc573, 0xc573, 0xc594, 0xc594, 0xc5b5, 0xbcf1, 0xa36a, 0xa349, 0xa349, 0xa308, 0x9ac7, 0x9ac7, 0x9ac7, 0x9ac7, 0x9ae7, 0x9ac7, 0x9ac7, 0x9ac7, 0x92a7, 0x92a7, 0x92a7, 0x9ac7, 0x9ac7, 0x9ac7, 0x9ac7, 0x9ac7, 0x9ae7, 0x9ae7, 0x9ae7, 0xa308, 0xa308, 0xa308, 0xa308, 0xa308, 0xab49, 0xab69, 0x92e8, 0x7a46, 0x7205, 0x7a46, 0x7a46, 0x8266, 0x8266, 0x8286, 0x8a87, 0x8a86, 0x8a87, 0x8aa7, 0x92a7, 0x92a7, 0x92a7, 0x92a7, 0x92a7, 0x92a7, 0x92a7, 0x92a6, 0x9286, 0x9286, 0x8a86, 0x9286, 0x92a6, 0x9286, 0x8a86, 0x8a86, 0x92a7, 0x92a7, 0x92c7, 0x9ac7, 0xa329, 0x8ac8, 0x41e7, 0xb533, 0xde56, 0xc573, 0xbd11,
		0xce16, 0xbd94, 0xbd73, 0xc573, 0xc594, 0xc594, 0xc594, 0xc594, 0xc594, 0xc594, 0xc573, 0xabec, 0xa349, 0xa349, 0xa328, 0x9ae8, 0x9ae8, 0x9ae8, 0x9ae8, 0x9ae7, 0x9ae7, 0x9ac7, 0x9ac7, 0x9ac7, 0x9ac7, 0x9ac7, 0x9ac7, 0x9ac7, 0x9ac7, 0x9ac7, 0x9ac7, 0x9ae7, 0x9ae7, 0x9ae7, 0xa2e8, 0xa308, 0xa308, 0xa328, 0xab49, 0xa308, 0x8a86, 0x7225, 0x7a26, 0x7a46, 0x8246, 0x8266, 0x8266, 0x8a66, 0x8a87, 0x8a86, 0x8a86, 0x8a87, 0x8a86, 0x9286, 0x8a86, 0x8a86, 0x9286, 0x8a86, 0x8a86, 0x9286, 0x9286, 0x8a86, 0x8a86, 0x8a86, 0x92a7, 0x92a7, 0x9286, 0x8a86, 0x8a86, 0x92a7, 0x92a7, 0x92a7, 0x92c7, 0x9ae8, 0xabcc, 0xe6d8, 0xe6b8, 0xcdb4, 0xbd52, 0xb4f1,
		0xbd73, 0xc573, 0xc594, 0xc594, 0xc594, 0xc594, 0xc573, 0xc594, 0xc594, 0xc594, 0xc5d5, 0xb4b0, 0xa36a, 0xa349, 0xa329, 0xa329, 0xa308, 0x9ae8, 0x9ae8, 0x9ae8, 0x9ae7, 0x9ac7, 0x9ac7, 0x9ae7, 0x9ae7, 0x9ac7, 0x9ac7, 0x9ac7, 0x9ac7, 0x9ac7, 0x9ac7, 0x9ae7, 0x9ae7, 0xa2e7, 0xa308, 0xa328, 0xab49, 0x9b08, 0x61e6, 0x28e3, 0x4143, 0x6a05, 0x7a46, 0x8246, 0x7a46, 0x8246, 0x8266, 0x8266, 0x8a66, 0x8266, 0x8a87, 0x8a87, 0x8a86, 0x8a86, 0x8a86, 0x8a86, 0x8a86, 0x8a86, 0x8a86, 0x8a86, 0x8a86, 0x8a86, 0x8a86, 0x8a87, 0x8a87, 0x8a86, 0x9287, 0x92a6, 0x92a7, 0x92a7, 0x92a7, 0x92a7, 0x9ac7, 0x9ac7, 0xbc4d, 0xeed8, 0xd5f5, 0xc573, 0xbd11, 0xacaf,
		0xbd74, 0xc594, 0xc594, 0xc573, 0xbd73, 0xbd73, 0xc573, 0xc574, 0xc594, 0xc594, 0xc5b5, 0xc573, 0xabab, 0xa349, 0x9b29, 0xa329, 0xa309, 0x9ae8, 0x92a7, 0x92a7, 0x9ac7, 0x92c7, 0x92c7, 0x9ae7, 0x9ae8, 0x9ac7, 0x9ae8, 0x9ac7, 0x9ac7, 0x9ac7, 0x9ac7, 0x9ae7, 0xa2e8, 0xa308, 0xa328, 0x92c8, 0x61e6, 0x28e3, 0x0842, 0x0862, 0x0862, 0x18a2, 0x3903, 0x59c5, 0x7206, 0x7a26, 0x7a46, 0x8266, 0x8266, 0x8266, 0x8266, 0x8a66, 0x8a66, 0x8a86, 0x8a86, 0x8a86, 0x8a86, 0x8a86, 0x8a87, 0x8a87, 0x8a86, 0x8a86, 0x8a87, 0x8a86, 0x8a86, 0x8a86, 0x8a86, 0x92a7, 0x92a7, 0x92a7, 0x92a7, 0x92c7, 0x9ae8, 0x9ae8, 0xbc4e, 0xde56, 0xcdb4, 0xbd52, 0xb4d0, 0xac8f,
		0xbd74, 0xbd73, 0xbd73, 0xbd73, 0xbd73, 0xbd73, 0xbd73, 0xc574, 0xc594, 0xc594, 0xc5b4, 0xc5d5, 0xb46f, 0xa329, 0x9b09, 0xa309, 0x9b08, 0x92c8, 0x8246, 0x7a26, 0x8a87, 0x8a87, 0x92a7, 0x92a7, 0x9ac7, 0x9ac7, 0x9ac7, 0x9ac7, 0x92c7, 0x9ac7, 0x9ae7, 0x9ae8, 0x9ac7, 0x7a46, 0x5185, 0x20c3, 0x0842, 0x1083, 0x1083, 0x1082, 0x1083, 0x1083, 0x0862, 0x1083, 0x5a68, 0x7288, 0x7226, 0x7a26, 0x7a46, 0x8246, 0x8266, 0x8266, 0x8266, 0x8266, 0x8a66, 0x8a86, 0x8a86, 0x8a86, 0x8a86, 0x8a86, 0x8a86, 0x8a87, 0x9287, 0x8a86, 0x9286, 0x9286, 0x9286, 0x92a7, 0x92a7, 0x9ac7, 0x9ac7, 0x9ac7, 0xa308, 0xa308, 0xbc6e, 0xcdf5, 0xc552, 0xb511, 0xacd0, 0xacaf,
		0xbd73, 0xbd73, 0xbd73, 0xbd73, 0xbd73, 0xbd73, 0xbd73, 0xbd94, 0xc594, 0xc594, 0xc5b4, 0xc5d5, 0xc573, 0x9b6b, 0x92e8, 0x9ae8, 0x92c8, 0x8a87, 0x8247, 0x7a47, 0x8246, 0x8a67, 0x8a87, 0x92a7, 0x92c7, 0x9ae8, 0x9ac7, 0x92a7, 0x92a7, 0x8a87, 0x7a46, 0x59a5, 0x3104, 0x1083, 0x0863, 0x0883, 0x10a3, 0x10a3, 0x1083, 0x1062, 0x1083, 0x10a3, 0x10a3, 0x18c3, 0x732b, 0x8bee, 0x7b4b, 0x72a9, 0x7aa8, 0x7a67, 0x7a26, 0x7a26, 0x8266, 0x8266, 0x8266, 0x8a66, 0x8a66, 0x8a66, 0x8a86, 0x8a87, 0x8a87, 0x92a7, 0x9287, 0x92a7, 0x9287, 0x9287, 0x92a7, 0x92a7, 0x92a7, 0x92a7, 0x9ac7, 0x9ac7, 0x9ae8, 0xa308, 0xb46f, 0xbd52, 0xacf1, 0xacb0, 0xacb0, 0xacb0,
		0xbd73, 0xbd73, 0xbd73, 0xbd73, 0xbd73, 0xbd73, 0xbd73, 0xc594, 0xc594, 0xc594, 0xc5b4, 0xc5b4, 0xc5d5, 0xac6f, 0x92e8, 0x8aa8, 0x8a87, 0x8246, 0x7a26, 0x7a26, 0x7a46, 0x8267, 0x8a87, 0x8aa7, 0x92c7, 0x92c7, 0x8287, 0x6a05, 0x5185, 0x2904, 0x18a3, 0x0883, 0x0883, 0x1083, 0x10a3, 0x10a3, 0x10a3, 0x10a3, 0x1083, 0x1082, 0x1082, 0x18a3, 0x10a3, 0x18e4, 0x7b4c, 0x9c70, 0x9c70, 0x9c4f, 0x9c70, 0x942f, 0x836c, 0x8b6b, 0x7aa8, 0x7a66, 0x8246, 0x8a86, 0x8a86, 0x8a86, 0x8a86, 0x8a86, 0x8a86, 0x8a87, 0x8a87, 0x8a86, 0x8a86, 0x8a86, 0x8a87, 0x8a87, 0x8a87, 0x8a87, 0x8a87, 0x92a7, 0x9ae8, 0xa329, 0xac6f, 0xacf1, 0xacb0, 0xacb0, 0xacb0, 0xac6f,
		0xbd53, 0xbd73, 0xbd53, 0xbd73, 0xbd73, 0xbd73, 0xbd73, 0xbd94, 0xc594, 0xc594, 0xc594, 0xc594, 0xc5d5, 0x7b8e, 0x8aea, 0x8aa8, 0x8267, 0x7a47, 0x7a26, 0x7a46, 0x7a46, 0x8267, 0x8aa7, 0x8aa7, 0x7226, 0x4965, 0x28e3, 0x1083, 0x0883, 0x1083, 0x10a3, 0x10a3, 0x10a3, 0x18a3, 0x18a3, 0x10a3, 0x18a3, 0x18a3, 0x1083, 0x1082, 0x1062, 0x18a3, 0x18c4, 0x20e4, 0x6b0b, 0x8c0e, 0xa4b1, 0xad13, 0xad13, 0xad13, 0xacf2, 0x942f, 0x730a, 0x7b2b, 0x93cd, 0x6268, 0x59c5, 0x7a67, 0x8287, 0x8a87, 0x92a7, 0x92a7, 0x8aa7, 0x8a86, 0x8a86, 0x8a66, 0x8266, 0x8266, 0x8267, 0x8267, 0x8266, 0x8a87, 0x92a7, 0xa349, 0xacb0, 0xacd0, 0xacd0, 0xb4d1, 0xac90, 0xa3ac,
		0xbd53, 0xbd53, 0xbd53, 0xbd53, 0xbd73, 0xbd73, 0xbd73, 0xbd73, 0xbd93, 0xbd93, 0xbd73, 0xbd73, 0xc594, 0x39c9, 0x41a7, 0x9b2a, 0x8a87, 0x7a47, 0x7a47, 0x7a47, 0x8267, 0x8a87, 0x7226, 0x3924, 0x1883, 0x1063, 0x1083, 0x1083, 0x18a4, 0x10a4, 0x18a3, 0x10a3, 0x10a3, 0x10a3, 0x18a3, 0x18a3, 0x18a3, 0x18a4, 0x1083, 0x1082, 0x1082, 0x18a3, 0x18c4, 0x2105, 0x7b8d, 0x7bad, 0x9470, 0xad33, 0xacf2, 0xa4b1, 0x9c4f, 0x8bad, 0x8bad, 0x9c70, 0x9450, 0x39c7, 0x41e7, 0x3165, 0x83ad, 0x3124, 0x4124, 0x51a5, 0x6a06, 0x7a26, 0x8267, 0x8a87, 0x8266, 0x8246, 0x8267, 0x8247, 0x8267, 0x8246, 0x92a7, 0x9b8b, 0xb512, 0xb4f1, 0xb4f1, 0xb4d0, 0xac2e, 0xab8c,
		0xbd53, 0xbd53, 0xbd53, 0xbd53, 0xbd73, 0xbd73, 0xbd73, 0xbd73, 0xbd73, 0xbd73, 0xbd73, 0xbd73, 0xad12, 0x2947, 0x0884, 0x51e7, 0x92e9, 0x8a87, 0x8247, 0x8267, 0x7a67, 0x51a6, 0x18a4, 0x1063, 0x10a3, 0x10a3, 0x10a3, 0x18a3, 0x18a4, 0x18a4, 0x18a4, 0x18a4, 0x10a4, 0x18a3, 0x18a4, 0x10a4, 0x10a3, 0x18a3, 0x10a3, 0x1083, 0x0862, 0x10a3, 0x18c4, 0x2125, 0x41e7, 0x5249, 0x5aab, 0xa4d2, 0xa4d2, 0x9c70, 0x942f, 0x942f, 0x9c90, 0xad12, 0xa4b1, 0x39a7, 0x39a6, 0x2904, 0x7bad, 0x2965, 0x0021, 0x0842, 0x1062, 0x20c4, 0x28e4, 0x4145, 0x59c5, 0x7246, 0x8267, 0x8267, 0x8247, 0x8a87, 0x8aa8, 0x20e5, 0x4208, 0xa4b1, 0xb4f1, 0xacb0, 0xac90, 0xac6f,
		0xb553, 0xbd73, 0xb553, 0xb553, 0xb553, 0xbd53, 0xb553, 0xb553, 0xb553, 0xb553, 0xb553, 0xbd93, 0x9450, 0x18e5, 0x18c4, 0x1083, 0x3125, 0x61e6, 0x61e6, 0x51a5, 0x3125, 0x10a4, 0x10a4, 0x18a3, 0x18a3, 0x10a3, 0x10a3, 0x10a3, 0x18a4, 0x18c4, 0x10a4, 0x10a4, 0x18a4, 0x18a3, 0x10a4, 0x10a3, 0x10a3, 0x10a3, 0x10a3, 0x1083, 0x1062, 0x10a3, 0x10a4, 0x31a7, 0x39c7, 0x7b8d, 0x41e8, 0x83ce, 0xa4d1, 0x9c70, 0x9c90, 0xa4d2, 0xacf2, 0xad13, 0x9c91, 0x5a69, 0x3986, 0x5a89, 0x4a28, 0x4a08, 0x0842, 0x18c4, 0x1062, 0x10a3, 0x1083, 0x1062, 0x1063, 0x20c3, 0x4144, 0x59a5, 0x61e6, 0x61e7, 0x2905, 0x1083, 0x2106, 0x8bce, 0xb4b0, 0xac6f, 0xac8f, 0xac8f,
		0xb553, 0xb553, 0xb553, 0xb553, 0xb553, 0xb553, 0xb552, 0xb552, 0xb553, 0xb533, 0xb532, 0xbd73, 0x6b4d, 0x10a4, 0x18c4, 0x18a4, 0x1063, 0x1062, 0x1083, 0x10a4, 0x18c5, 0x18e4, 0x18c4, 0x18a3, 0x10a3, 0x10a3, 0x18a3, 0x18a3, 0x18a4, 0x18a4, 0x18a4, 0x10a4, 0x10a4, 0x10a3, 0x10a3, 0x10a3, 0x10a3, 0x10a3, 0x10a3, 0x1083, 0x1082, 0x1083, 0x18c4, 0x31a7, 0x3986, 0x3187, 0x3186, 0x9430, 0xad12, 0xa4f2, 0xacf2, 0xacf2, 0xad12, 0xacf2, 0x944f, 0x83ad, 0x3986, 0x41c7, 0x62eb, 0x83ad, 0x2104, 0x18a3, 0x18a3, 0x1083, 0x1883, 0x1083, 0x1083, 0x1083, 0x1083, 0x1062, 0x1063, 0x18a4, 0x2105, 0x2946, 0x2967, 0x832c, 0xb3ed, 0xa3ac, 0xa38b, 0xa36c,
		0xb553, 0xb553, 0xb532, 0xb532, 0xb532, 0xb532, 0xb532, 0xb512, 0xb512, 0xacf1, 0xacf1, 0xad11, 0x4a2a, 0x10a4, 0x18a4, 0x18a3, 0x1083, 0x1083, 0x1083, 0x18a4, 0x18e5, 0x18c4, 0x18c4, 0x18a4, 0x10a3, 0x10a3, 0x1883, 0x1883, 0x18a4, 0x18a4, 0x10a4, 0x10a4, 0x18a4, 0x18a4, 0x10a3, 0x10a3, 0x10a3, 0x10a3, 0x10a3, 0x1083, 0x1082, 0x10a3, 0x10a3, 0x4a49, 0x4a28, 0x7b8d, 0x4208, 0x6b0c, 0xad33, 0xacf2, 0xacf2, 0xacf2, 0xad13, 0xa4b1, 0x942f, 0x8c0e, 0x8bce, 0x942f, 0xa4d2, 0x9c70, 0x732c, 0x18a3, 0x18c4, 0x18a3, 0x1083, 0x1083, 0x1883, 0x1883, 0x18a3, 0x18a3, 0x1883, 0x1883, 0x20e4, 0x2926, 0x2126, 0x82eb, 0xb3ac, 0xab4b, 0xa32a, 0xa30a,
		0xb532, 0xb532, 0xad12, 0xad12, 0xad12, 0xad12, 0xacf1, 0xacf1, 0xacd0, 0xa4b0, 0xa4af, 0x9c6f, 0x3167, 0x10a4, 0x18a4, 0x10a3, 0x1083, 0x1082, 0x1083, 0x18a4, 0x18c5, 0x18c5, 0x18c4, 0x18c4, 0x10a3, 0x10a3, 0x10a3, 0x18a3, 0x18a4, 0x18a4, 0x10c4, 0x10a4, 0x18a4, 0x18a4, 0x10a4, 0x10a3, 0x10a3, 0x10a3, 0x10a3, 0x1083, 0x1083, 0x10a3, 0x10a3, 0x5249, 0x39e7, 0x39a7, 0x4a08, 0x9470, 0xa4f2, 0xa4d2, 0xa4d2, 0xa4d2, 0xa4f2, 0x9c90, 0x944f, 0x9470, 0xa4d1, 0xa4d2, 0xad13, 0x944f, 0xa4d1, 0x5a89, 0x1083, 0x20e4, 0x1083, 0x1083, 0x1883, 0x1883, 0x18a3, 0x18a4, 0x18a4, 0x1863, 0x20c4, 0x2926, 0x2106, 0x82ea, 0xab8b, 0xa32a, 0xa32b, 0xab4b,
		0xad12, 0xad12, 0xacf1, 0xacf1, 0xa4d1, 0xacd1, 0xa4b0, 0xa4b0, 0xa48f, 0xa46f, 0x9c6e, 0x83ac, 0x20e5, 0x18a4, 0x18a4, 0x10a4, 0x1083, 0x1062, 0x1083, 0x18a4, 0x18c4, 0x18c4, 0x18c4, 0x18c4, 0x10a4, 0x10a3, 0x10a3, 0x18a3, 0x18a4, 0x18a4, 0x10a4, 0x10a4, 0x18a4, 0x18a4, 0x10a4, 0x10a3, 0x10a3, 0x10a3, 0x10a3, 0x1083, 0x1083, 0x10a3, 0x10a3, 0x41e8, 0x8bee, 0x7b8d, 0x8c50, 0xa4d2, 0xa4b1, 0x9cb1, 0x9cb1, 0x9cb1, 0xa4d2, 0x9c90, 0x9450, 0x9cb1, 0xacf2, 0xad13, 0xb554, 0x83ad, 0x5aaa, 0x8c2f, 0x39a7, 0x1083, 0x20c4, 0x1883, 0x1883, 0x1883, 0x1883, 0x18a4, 0x18a4, 0x1883, 0x18a3, 0x2926, 0x2106, 0x82aa, 0xab6b, 0xa32b, 0xab2b, 0xab6c,
		0xa4f1, 0xa4d1, 0xacd1, 0xa4b0, 0xa490, 0xa490, 0xa48f, 0x9c4e, 0x942d, 0x940d, 0x9c2d, 0x730b, 0x18a4, 0x18a4, 0x18a4, 0x18a4, 0x18c4, 0x18c4, 0x10a3, 0x1083, 0x10a4, 0x10a4, 0x18a4, 0x18c4, 0x18a4, 0x10a4, 0x1083, 0x1083, 0x10a4, 0x10a4, 0x10a4, 0x10a4, 0x10a4, 0x18a4, 0x10a4, 0x10a3, 0x10a3, 0x1083, 0x1083, 0x1083, 0x1083, 0x10a3, 0x10c3, 0x39a6, 0x942f, 0xa4f2, 0xa4b1, 0x9c90, 0x9c90, 0x9c91, 0x9c70, 0x9c70, 0x83ce, 0x83ae, 0xa4b1, 0xad13, 0xad13, 0xad13, 0xb574, 0x5a8a, 0x49e8, 0x6b0c, 0x9450, 0x41c7, 0x1883, 0x18c4, 0x1862, 0x1883, 0x1883, 0x18a3, 0x18a3, 0x18a4, 0x1883, 0x20e5, 0x18e5, 0x7a8a, 0xb36b, 0xab4b, 0xb36c, 0xb3ad,
		0xa4d0, 0xa4b0, 0xa46f, 0x9c6f, 0x9c6f, 0x9c4e, 0x940d, 0x8bcc, 0x8bcc, 0x9c0d, 0xacaf, 0x5aab, 0x1084, 0x18c4, 0x18c4, 0x18a4, 0x18a4, 0x18e5, 0x1905, 0x18e5, 0x10a3, 0x1063, 0x1083, 0x10a3, 0x10a4, 0x1083, 0x1083, 0x1083, 0x1083, 0x10a3, 0x10a3, 0x10a3, 0x10a3, 0x10a4, 0x10a4, 0x10a3, 0x10a3, 0x1083, 0x1083, 0x1083, 0x1083, 0x10a3, 0x18c4, 0x3986, 0x734c, 0x9cb1, 0x944f, 0x944f, 0x9470, 0x9470, 0x83ce, 0x526a, 0x7bae, 0x41e8, 0x8c30, 0xb554, 0xad13, 0xad33, 0xbd75, 0x5a8a, 0x4a08, 0x41e8, 0x9cb1, 0xa4d1, 0x4a28, 0x1883, 0x1883, 0x1082, 0x1883, 0x1883, 0x1883, 0x1883, 0x18a3, 0x18a4, 0x20e5, 0x51e8, 0xb38c, 0xb3cd, 0xbc0f, 0xc470,
		0x9c8f, 0x9c6f, 0x9c4e, 0x9c4e, 0x93ed, 0x8bcc, 0x8bcc, 0x93ec, 0x9c4d, 0xa48f, 0xacd0, 0x4209, 0x10a4, 0x18a4, 0x18a4, 0x18a4, 0x18a4, 0x18c4, 0x18e5, 0x2126, 0x2126, 0x18c4, 0x18a4, 0x10a4, 0x10a3, 0x10a3, 0x10a3, 0x10a3, 0x1083, 0x1083, 0x1083, 0x10a3, 0x1083, 0x10a3, 0x10a3, 0x10a3, 0x10a3, 0x1083, 0x1083, 0x1083, 0x1083, 0x10a3, 0x18c4, 0x39a6, 0x62ca, 0x9450, 0x9c91, 0x9450, 0x9c70, 0x9cb1, 0xad13, 0x524a, 0x4a29, 0x41c8, 0x9471, 0xb554, 0xad33, 0xad13, 0xb574, 0x8c0f, 0x3125, 0x5249, 0x9451, 0x9cb2, 0xa4f2, 0x5229, 0x1042, 0x1883, 0x1883, 0x1883, 0x1883, 0x1883, 0x18a3, 0x18a4, 0x18c5, 0x3967, 0xb38c, 0xbbed, 0xbc2f, 0xc450,
		0x9c4e, 0x942d, 0x940d, 0x8bcc, 0x8bab, 0x93ec, 0x9c2d, 0x9c6f, 0xa48f, 0xacd0, 0x942f, 0x2127, 0x18a4, 0x18a4, 0x18a4, 0x18a4, 0x18a4, 0x18a4, 0x18e5, 0x2126, 0x2106, 0x18c5, 0x18e5, 0x18c4, 0x10a4, 0x18a4, 0x18c4, 0x18a4, 0x10a3, 0x10a3, 0x10a3, 0x10a3, 0x10a3, 0x10a3, 0x10a3, 0x1083, 0x1083, 0x1083, 0x1083, 0x1083, 0x1083, 0x1083, 0x18c4, 0x41c6, 0x62aa, 0x8c0f, 0xa4d2, 0x9cb1, 0xa4d2, 0xa4f3, 0xb554, 0x6aec, 0x528a, 0x5249, 0x734d, 0xbd74, 0xad33, 0xad13, 0xb554, 0xa4b1, 0x7b6d, 0x5249, 0x526a, 0x83ce, 0xa4f2, 0xa4d2, 0x3125, 0x1062, 0x1883, 0x1883, 0x1883, 0x1883, 0x1883, 0x18a4, 0x18a4, 0x3967, 0xb3ed, 0xc44f, 0xc450, 0xc450,
		0x8bec, 0x8bab, 0x8bcc, 0x93ec, 0x9c2d, 0x9c4e, 0x9c8f, 0xa4af, 0xa4b0, 0xb531, 0x6b2c, 0x18c5, 0x18a4, 0x18a4, 0x18a4, 0x10a4, 0x10a4, 0x18a4, 0x18c5, 0x18e6, 0x2106, 0x18e5, 0x18e5, 0x18c4, 0x10a4, 0x10c4, 0x18c4, 0x10a4, 0x10a3, 0x10a3, 0x18a4, 0x10a4, 0x10a3, 0x10a3, 0x10a3, 0x1083, 0x1083, 0x1083, 0x1083, 0x1083, 0x1083, 0x1083, 0x20e4, 0x4a07, 0x62ca, 0x8c0e, 0x9cb1, 0xa4f2, 0xad13, 0xad13, 0xb554, 0x7bae, 0x6b2c, 0x5acb, 0x5acb, 0xacf3, 0xad13, 0xad13, 0xb554, 0x9cb1, 0x8c0f, 0x9c91, 0xa4d2, 0xa4f3, 0xa4f2, 0xb574, 0x736d, 0x1042, 0x1883, 0x1883, 0x1883, 0x1883, 0x1883, 0x18a3, 0x1884, 0x3166, 0xbc91, 0xccd2, 0xccd2, 0xd4d3
};
/* USER CODE END PV */

void SystemClock_Config(void);
/* USER CODE BEGIN PFP */
/* Private function prototypes -----------------------------------------------*/

/* USER CODE END PFP */

/* USER CODE BEGIN 0 */
void ILI9341_Draw_PartImage(const uint16_t* image, uint16_t x, uint16_t y, uint16_t w, uint16_t h)
{
    ILI9341_Set_Address(x, y, x + w - 1, y + h - 1);

    ILI9341_Write_Command(0x2C);
    for (uint32_t i = 0; i < w * h; i++)
    {
        ILI9341_Write_Data(image[i] >> 8);
        ILI9341_Write_Data(image[i] & 0xFF);
    }
}
uint16_t CRC16_2(uint8_t *ptr, uint8_t length)
{
	uint16_t crc = 0xFFFF;
	uint8_t s = 0x00;
	while(length--){
		crc ^= *ptr++;
		for(s = 0; s < 8;s++)
		{
			if((crc & 0x01) != 0){
				crc >>= 1;
				crc ^= 0xA001;
			}else crc >>= 1;
		}
	}
	return crc;
}
uint16_t RGB565(uint8_t r, uint8_t g, uint8_t b) {
    return ((r & 0xF8) << 8) |
           ((g & 0xFC) << 3) |
           (b >> 3);
}
uint16_t LightenColor(uint16_t color, uint8_t percent)
{
    if (percent > 100) percent = 100;

    uint8_t r = (color >> 11) & 0x1F;
    uint8_t g = (color >> 5)  & 0x3F;
    uint8_t b =  color        & 0x1F;

    uint8_t rMax = 31;
    uint8_t gMax = 63;
    uint8_t bMax = 31;

    r = r + ((rMax - r) * percent) / 100;
    g = g + ((gMax - g) * percent) / 100;
    b = b + ((bMax - b) * percent) / 100;

    return (r << 11) | (g << 5) | b;
}
void ShowColor(uint16_t color, uint8_t percent, uint16_t position_y)
{
    ILI9341_Draw_Filled_Circle(20, position_y, 15, color);
    ILI9341_Draw_Rectangle(60, position_y - 10, 120, 20, LightenColor(color, 50));
    uint16_t filledWidth = (120 * percent) / 100;
    ILI9341_Draw_Rectangle(60, position_y - 10, filledWidth, 20, color);
    char buf[10];
    sprintf(buf, "%d %%", percent);
    ILI9341_Draw_Text(buf, 200, position_y, BLACK, 2, WHITE);
}
void ShowTemperture()
{
	char temp[10];
		sprintf(temp, "%4.1f C", t);
		ILI9341_Draw_Text(temp, 20, 20, BLACK, 2, WHITE);
		ILI9341_Draw_Filled_Circle(130, 30, 15, RGB565(red, green, blue));
		char humid[10];
		sprintf(humid, "%4.1f %%RH", h);
		ILI9341_Draw_Text(humid, 170, 20, BLACK, 2, WHITE);
}
void DisplayMenu()
{
	ILI9341_Fill_Screen(WHITE);
	ILI9341_Set_Rotation(SCREEN_HORIZONTAL_1);
	ShowTemperture();
	ShowColor(RED, red_percent, 80);
	ShowColor(GREEN, green_percent, 140);
	ShowColor(BLUE, blue_percent, 200);
}
void UpdateColor(uint8_t *color, uint8_t *percent)
{
    *percent = (*percent + 10) % 110;
    *color = (uint8_t)((*percent * 255) / 100);
    DisplayMenu();
}
void DisplayProfile(const uint16_t* image, const char *fn, const char *ln, int number)
{
    ILI9341_Fill_Screen(WHITE);
    ILI9341_Set_Rotation(SCREEN_HORIZONTAL_1);
    ILI9341_Draw_PartImage(image, 20, 60, 80, 100);
    static char firstname[20];
    sprintf(firstname, "%s", fn);
    static char lastname[20];
    sprintf(lastname, "%s", ln);
    static char studentId[10];
    sprintf(studentId, "%d", number);
    ILI9341_Draw_Text("GROUP NO.6", 120, 50, RGB565(red, green, blue), 2, WHITE);
    ILI9341_Draw_Text(firstname, 120, 100, RGB565(red, green, blue), 2, WHITE);
    ILI9341_Draw_Text(lastname, 120, 150, RGB565(red, green, blue), 2, WHITE);
    ILI9341_Draw_Text(studentId, 120, 200, RGB565(red, green, blue), 2, WHITE);
}
/* USER CODE END 0 */

int main(void)
{

  /* Enable the CPU Cache */

  /* Enable I-Cache---------------------------------------------------------*/
  SCB_EnableICache();

  /* Enable D-Cache---------------------------------------------------------*/
  SCB_EnableDCache();

  /* MCU Configuration--------------------------------------------------------*/

  /* Reset of all peripherals, Initializes the Flash interface and the Systick. */
  HAL_Init();

  /* USER CODE BEGIN Init */
  uint8_t cmdBuffer[3];
  uint8_t dataBuffer[8];
  volatile uint32_t adc_val = 0;
  float adc = 0;
  /* USER CODE END Init */

  /* Configure the system clock */
  SystemClock_Config();

  /* Initialize all configured peripherals */
  MX_GPIO_Init();
  MX_USART3_UART_Init();
  MX_SPI5_Init();
  MX_TIM1_Init();
  MX_RNG_Init();
  MX_I2C1_Init();
  MX_ADC1_Init();
  MX_TIM2_Init();
  /* USER CODE BEGIN 2 */
  ILI9341_Init();//initial driver setup to drive ili9341
  State state = MENU;
  DisplayMenu();
  cmdBuffer[0] = 0x03;
  cmdBuffer[1] = 0x00;
  cmdBuffer[2] = 0x04;
  HAL_ADC_Start(&hadc1);
  HAL_TIM_PWM_Start(&htim2, TIM_CHANNEL_4);
  /* USER CODE END 2 */

  /* Infinite loop */
  while (1)
  {

    /* USER CODE BEGIN 3 */
	  if(HAL_ADC_PollForConversion(&hadc1, 100) == HAL_OK)
	  {
		  adc_val = HAL_ADC_GetValue(&hadc1);
		  adc = (float)adc_val / 4095.0f;
		  if(adc < 0.2)
			  adc = 0.2f;
		  htim2.Instance -> CCR4 = (uint32_t)((10000 - 1) * adc);
	  }
	  switch(state)
	  {
	  	  case MENU:
	  		  profile_counter = 0;
	  		  if(TP_Touchpad_Pressed())
	  		  {
	  			  uint16_t position_array[2];
	  			  if(TP_Read_Coordinates(position_array) == TOUCHPAD_DATA_OK)
	  			  {
	  				  uint16_t x_pos = position_array[0];
	  				  uint16_t y_pos = position_array[1];

	  	    	       if((150 - x_pos) * (150 - x_pos) + (40 - y_pos) * (40 - y_pos) <= 15*15)
	  	    	       {
	  	    	    	   UpdateColor(&red, &red_percent);
	  	    	       }
	  	    	       if((100 - x_pos) * (100 - x_pos) + (40 - y_pos) * (40 - y_pos) <= 15*15)
	  	    	       {
	  	    	    	   UpdateColor(&green, &green_percent);
	  	    	       }
	  	    	       if((50 - x_pos) * (50 - x_pos) + (40 - y_pos) * (40 - y_pos) <= 15*15)
	  	    	       {
	  	    	    	   UpdateColor(&blue, &blue_percent);
	  	    	       }
	  	    	       if((210 - x_pos) * (210 - x_pos) + (140 - y_pos) * (140 - y_pos) <= 15*15)
	  	    	       {
	  	    	    	   state = PROFILE;
	  	    	    	   DisplayProfile(bill, "Rachchanon", "Klaisuban", 66010695);
	  	    	    	   profile_active = 1;
	  	    	    	   profile_counter = 0;
	  	    	    	   HAL_TIM_Base_Start_IT(&htim1);00
	  	    	    	   break;
	  	    	       }
	  			  }
	  		  }
	  		  HAL_I2C_Master_Transmit(&hi2c1, 0x5c<<1, cmdBuffer, 3, 200);
	  		  HAL_Delay(2);
	  		  HAL_I2C_Master_Transmit(&hi2c1, 0x5c<<1, cmdBuffer, 3, 200);
	  		  HAL_Delay(2);
	  		  HAL_I2C_Master_Receive(&hi2c1, 0x5c<<1, dataBuffer, 8, 200);
	  		  uint16_t Rcrc = dataBuffer[7] << 8;
	  		  Rcrc += dataBuffer[6];
	  		  if(Rcrc == CRC16_2(dataBuffer, 6)){
	  			  	  uint16_t tempertature = ((dataBuffer[4] & 0x7F) << 8) + dataBuffer[5];
	  			  	  t = tempertature / 10.0;
	  			  	  t = (((dataBuffer[4] & 0x80) >> 7) == 1) ? (t * (-1)) : t;
	  			  	  uint16_t humidity = (dataBuffer[2] << 8) + dataBuffer[3];
	  			  	  h = humidity / 10.0;
	  			  	  ShowTemperture();
	  		  }
	  		  break;
	  	  case PROFILE:
	  		  if(TP_Touchpad_Pressed())
	  		  {
	  			  uint16_t position_array[2];
	  			  if(TP_Read_Coordinates(position_array) == TOUCHPAD_DATA_OK)
	  			  {
	  				  uint16_t x_pos = position_array[0];
	  				  uint16_t y_pos = position_array[1];

	  				if(x_pos >= 100 && x_pos <= 160 &&
	  				   y_pos >= 40 && y_pos <= 120)
	  			  	  {
	  						profile_active = 0;
	  						profile_counter = 0;
	  						HAL_TIM_Base_Stop_IT(&htim1);
	  						state = MENU;
	  						DisplayMenu();
	  			  	  }
	  			  }
	  		  }
	  		  if(profile_counter >= 5)
	  		  {
	  			  profile_active = 0;
	  			  profile_counter = 0;
	  			  HAL_TIM_Base_Stop_IT(&htim1);
	  			  state = MENU;
	  			  DisplayMenu();
	  	    	}
	  	    	break;
	  	    default:
	  	    	break;
	 }
  }
  /* USER CODE END 3 */
}

void SystemClock_Config(void)
{
  RCC_OscInitTypeDef RCC_OscInitStruct = {0};
  RCC_ClkInitTypeDef RCC_ClkInitStruct = {0};

  /** Configure LSE Drive Capability
  */
  HAL_PWR_EnableBkUpAccess();

  /** Configure the main internal regulator output voltage
  */
  __HAL_RCC_PWR_CLK_ENABLE();
  __HAL_PWR_VOLTAGESCALING_CONFIG(PWR_REGULATOR_VOLTAGE_SCALE1);

  /** Initializes the RCC Oscillators according to the specified parameters
  * in the RCC_OscInitTypeDef structure.
  */
  RCC_OscInitStruct.OscillatorType = RCC_OSCILLATORTYPE_HSE;
  RCC_OscInitStruct.HSEState = RCC_HSE_BYPASS;
  RCC_OscInitStruct.PLL.PLLState = RCC_PLL_ON;
  RCC_OscInitStruct.PLL.PLLSource = RCC_PLLSOURCE_HSE;
  RCC_OscInitStruct.PLL.PLLM = 4;
  RCC_OscInitStruct.PLL.PLLN = 200;
  RCC_OscInitStruct.PLL.PLLP = RCC_PLLP_DIV2;
  RCC_OscInitStruct.PLL.PLLQ = 9;
  RCC_OscInitStruct.PLL.PLLR = 2;
  if (HAL_RCC_OscConfig(&RCC_OscInitStruct) != HAL_OK)
  {
    Error_Handler();
  }

  /** Activate the Over-Drive mode
  */
  if (HAL_PWREx_EnableOverDrive() != HAL_OK)
  {
    Error_Handler();
  }

  /** Initializes the CPU, AHB and APB buses clocks
  */
  RCC_ClkInitStruct.ClockType = RCC_CLOCKTYPE_HCLK|RCC_CLOCKTYPE_SYSCLK
                              |RCC_CLOCKTYPE_PCLK1|RCC_CLOCKTYPE_PCLK2;
  RCC_ClkInitStruct.SYSCLKSource = RCC_SYSCLKSOURCE_PLLCLK;
  RCC_ClkInitStruct.AHBCLKDivider = RCC_SYSCLK_DIV1;
  RCC_ClkInitStruct.APB1CLKDivider = RCC_HCLK_DIV4;
  RCC_ClkInitStruct.APB2CLKDivider = RCC_HCLK_DIV2;

  if (HAL_RCC_ClockConfig(&RCC_ClkInitStruct, FLASH_LATENCY_6) != HAL_OK)
  {
    Error_Handler();
  }
}

void Error_Handler(void)
{
  while(1)
  {
  }
}
